VERSION "Version"

NS_ :

BS_:

BU_: CCU ADC FAPA IFC FLR FRR RRR RLR INU Tester CBM VIU SRS IDC PCS AMP IMR FIMR TBOX IBCS IXCU V2XOBU WHUD RLBMS CCURT2 RT2_C3 OTAWL ZCUF ZCUL ZCUR ZCUT IPS DCU NIDU RBM WACUFL IID CCURT1 RT1_C0 RT1_C1 AVAS FLLCM FRLCM RLLCMA RRLCMA RLLCMB RRLCMB LBMS LBMSAD MFS FCP IDU ITS BCB DCDC PCU EOP DCU2 BMS TMC EPS ECS CD PAS SBM WCM ETC TBOX2 DSM FLPDM FRPDM RLPDM RRPDM HVSMR SCMRL SCMRR EBU EPB VDC EVCC ADM PLGM FBLCM RLISD RRISD RCP RFR WCMFR SCMR TFOAR TROAR HVSPRL HVSPRR

BO_ 904 CCU_GwMsg_4: 64 CCU
 SG_ CCU_GwMsg_4_CRC : 7|16@0+ (1,0) [0|65535] ""  ADC
 SG_ CCU_GwMsg_4_Counter : 23|8@0+ (1,0) [0|255] ""  ADC
 SG_ HVAC_RearDefrostSt : 24|1@0+ (1,0) [0|1] ""  ADC
 SG_ HVAC_WindExitMode : 27|3@0+ (1,0) [0|7] ""  ADC
 SG_ HVAC_CorrectedExterTemp : 39|8@0+ (0.5,-40) [-40|87.5] "°C"  ADC
 SG_ HVAC_CorrectedExterTempVD : 28|1@0+ (1,0) [0|1] ""  ADC
 SG_ HVAC_CorrectedCabinTemp : 47|8@0+ (0.5,-40) [-40|87.5] "°C"  ADC
 SG_ HVAC_CorrectedCabinTempVD : 29|1@0+ (1,0) [0|1] ""  ADC
 SG_ WW_FwpFaultSt : 30|1@0+ (1,0) [0|1] ""  ADC
 SG_ WW_RwpFaultSt : 31|1@0+ (1,0) [0|1] ""  ADC
 SG_ WW_FwshFaultSt : 48|1@0+ (1,0) [0|1] ""  ADC
 SG_ WW_RwshFaultSt : 49|1@0+ (1,0) [0|1] ""  ADC
 SG_ WW_FwpAutoModeSt : 50|1@0+ (1,0) [0|1] ""  ADC
 SG_ WW_RainFallLevel : 55|4@0+ (1,0) [0|15] ""  ADC
 SG_ RLS_LightOnReq : 51|1@0+ (1,0) [0|1] ""  ADC
 SG_ RLS_LampOnReqValid : 60|1@0+ (1,0) [0|1] ""  ADC
 SG_ RLS_WiperSpd : 59|4@0+ (1,0) [0|15] ""  ADC
 SG_ RLS_AMBBrightness : 69|14@0+ (6,0) [0|98286] "Lux"  ADC
 SG_ RLS_FWBrightness : 87|14@0+ (6,0) [0|98286] ""  ADC
 SG_ RLS_RainfallLevel : 103|4@0+ (1,0) [0|15] ""  ADC
 SG_ RLS_RSErr : 88|1@0+ (1,0) [0|1] ""  ADC
 SG_ RLS_LSErr : 89|1@0+ (1,0) [0|1] ""  ADC
 SG_ PM_AUTHPstState : 70|1@0+ (1,0) [0|1] ""  ADC
 SG_ CCU_FuncReq_SentryMod : 71|1@0+ (1,0) [0|1] ""  ADC
 SG_ RLS_WindShieldHum : 111|8@0+ (0.5,-0.5) [0|100] "%"  ADC
 SG_ RLS_WindShieldTem : 119|8@0+ (0.5,-40) [-40|86.5] "℃"  ADC
 SG_ RLS_DewPoint : 127|8@0+ (0.5,-40) [-40|86.5] "℃"  ADC
 SG_ CCU_ModeSuppressSts : 62|2@0+ (1,0) [0|2] ""  ADC
 SG_ RLS_HUTErr : 63|1@0+ (1,0) [0|1] ""  ADC
 SG_ SR_SunroofCurrentPst : 135|8@0+ (0.5,0) [0|255] "%"  ADC
 SG_ EL_LeftBSDIndicatorSt : 136|1@0+ (1,0) [0|1] ""  ADC
 SG_ UINM_HazardLightSwSt : 137|1@0+ (1,0) [0|1] ""  ADC
 SG_ EL_MLTurnLightSt : 139|2@0+ (1,0) [0|3] ""  ADC
 SG_ EL_MLTurnLightFaultSt : 140|1@0+ (1,0) [0|1] ""  ADC
 SG_ EL_LeftBSDIndicatorFaultSt : 141|1@0+ (1,0) [0|1] ""  ADC
 SG_ ZCUL_FrtWindshildHeatSt : 143|2@0+ (1,0) [0|3] ""  ADC
 SG_ ACU_PCS_SVM_MODCmd : 96|1@0+ (1,0) [0|1] ""  ADC
 SG_ ACU_HeadLightVirtualSwSt : 99|3@0+ (1,0) [0|7] ""  ADC
 SG_ ACU_FrontFogLightVirtualSwSt : 144|1@0+ (1,0) [0|1] ""  ADC
 SG_ ACU_RearFogLightVirtualSwSt : 145|1@0+ (1,0) [0|1] ""  ADC
 SG_ ACU_Account_Uid : 151|4@0+ (1,0) [0|15] ""  ADC
 SG_ ACU_IHBC_SwitchReq : 147|2@0+ (1,0) [0|3] ""  ADC
 SG_ ACU_NDASwitchReq : 153|2@0+ (1,0) [0|3] ""  ADC
 SG_ ACU_NDALCConSwitchReq : 155|2@0+ (1,0) [0|3] ""  ADC
 SG_ ACU_NDALCStySwitchReq : 157|2@0+ (1,0) [0|3] ""  ADC
 SG_ ACU_ADASWarnTypeSwitch : 159|2@0+ (1,0) [0|3] ""  ADC
 SG_ ACU_iACC_StyleConfirmSwitchReq : 177|2@0+ (1,0) [0|3] ""  ADC
 SG_ ACU_IFC_SpeedLimit : 167|8@0+ (1,0) [0|255] "km/h"  ADC
 SG_ ACU_IFC_ISDRestOfdis : 175|8@0+ (1,0) [0|70] "km"  ADC
 SG_ EL_MLADASLightSt : 181|2@0+ (1,0) [0|3] ""  ADC
 SG_ ACU_IFC_SpeedLimitUnit : 183|2@0+ (1,0) [0|3] ""  ADC
 SG_ ACU_ThemeType : 196|1@0+ (1,0) [0|1] ""  ADC
 SG_ ACU_IFC_SpeedLimtType : 187|4@0+ (1,0) [0|15] ""  ADC
 SG_ ACU_IFC_RoadType : 191|4@0+ (1,0) [0|15] ""  ADC
 SG_ ACU_IFC_ZoneCode : 199|3@0+ (1,0) [0|7] ""  ADC
 SG_ ACU_IFC_NaviSt : 195|2@0+ (1,0) [0|3] ""  ADC
 SG_ ACU_IFC_NaviCorp : 207|3@0+ (1,0) [0|7] ""  ADC
 SG_ ACU_IFC_NaviNewIconDis : 204|5@0+ (0.1,0) [0|2] "km"  ADC
 SG_ ACU_IFC_OfframpSt : 192|1@0+ (1,0) [0|1] ""  ADC
 SG_ ACU_IFC_NaviNewIcon : 211|4@0+ (1,0) [0|15] ""  ADC
 SG_ ACU_IFC_SLCAheadDis : 223|8@0+ (5,0) [0|1250] "m"  ADC
 SG_ ACU_DVR_Switch : 193|1@0+ (1,0) [0|1] ""  ADC
 SG_ ACU_IFC_OfframpDis : 231|8@0+ (10,0) [0|2000] "m"  ADC
 SG_ SSW_FLSeatSlideCurrentPst : 239|8@0+ (0.5,0) [0|100] "%"  ADC
 SG_ SSW_FLSeatHeightCurrentPst : 247|8@0+ (0.5,0) [0|100] "%"  ADC
 SG_ SSW_FLSeatBackrestCurrentPst : 255|8@0+ (0.5,0) [0|100] "%"  ADC
 SG_ DrvrSideMotResp : 263|4@0+ (1,0) [0|15] ""  ADC
 SG_ EL_LeftLowBeamSt : 256|1@0+ (1,0) [0|1] ""  ADC
 SG_ EL_LeftLowBeamFaultSt : 257|1@0+ (1,0) [0|1] ""  ADC
 SG_ EL_RightLowBeamSt : 258|1@0+ (1,0) [0|1] ""  ADC
 SG_ EL_RightLowBeamFaultSt : 259|1@0+ (1,0) [0|1] ""  ADC
 SG_ WW_FWPMotorSt : 271|3@0+ (1,0) [0|7] ""  ADC
 SG_ EL_FLTurnLightSt : 268|2@0+ (1,0) [0|3] ""  ADC
 SG_ EL_FLTurnLightFaultSt : 266|1@0+ (1,0) [0|1] ""  ADC
 SG_ EL_FRTurnLightSt : 265|2@0+ (1,0) [0|3] ""  ADC
 SG_ EL_FRTurnLightFaultSt : 279|1@0+ (1,0) [0|1] ""  ADC
 SG_ EL_SideBrkLightSt : 278|1@0+ (1,0) [0|1] ""  ADC
 SG_ EL_SideBrkLightFaultSt : 277|1@0+ (1,0) [0|1] ""  ADC
 SG_ EL_CHMSLSt : 276|1@0+ (1,0) [0|1] ""  ADC
 SG_ EL_CHMSLFaultSt : 275|1@0+ (1,0) [0|1] ""  ADC
 SG_ EL_RLTurnLightSt : 274|2@0+ (1,0) [0|3] ""  ADC
 SG_ EL_RLTurnLightFaultSt : 272|1@0+ (1,0) [0|1] ""  ADC
 SG_ EL_RRTurnLightSt : 287|2@0+ (1,0) [0|3] ""  ADC
 SG_ EL_RRTurnLightFaultSt : 285|1@0+ (1,0) [0|1] ""  ADC
 SG_ IPS_DCDCModeSt : 298|3@0+ (1,0) [0|7] ""  OTAWL,ADC
 SG_ IPDS_FRRadarPowerSup : 309|2@0+ (1,0) [0|3] ""  ADC
 SG_ IPDS_FLRadarPowerSup : 307|2@0+ (1,0) [0|3] ""  ADC
 SG_ IPDS_FrontRadarPowerSup : 305|2@0+ (1,0) [0|3] ""  ADC
 SG_ IPDS_HDMapPowerSup : 319|2@0+ (1,0) [0|3] ""  ADC
 SG_ IPDS_RearRadarPowerSup : 317|2@0+ (1,0) [0|3] ""  ADC

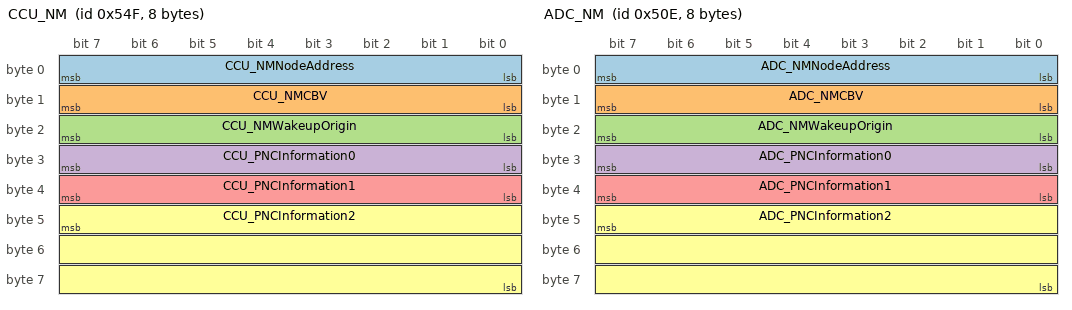
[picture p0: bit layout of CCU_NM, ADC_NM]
BO_ 1359 CCU_NM: 8 CCU
 SG_ CCU_NMNodeAddress : 7|8@0+ (1,0) [0|255] ""  ZCUF,ZCUL,ZCUR,ZCUT,ADM,LBMS,MFS,IDU,ITS,IPS,PCU,DCU,DCU2,NIDU,BMS,EVCC,TMC,RBM,IBCS,ECS,RLBMS,EPB,IXCU,WACUFL,IDC,IID,AMP,ADC,FAPA,VIU,IFC,TBOX,FLPDM,FRPDM,RLPDM,RRPDM,PLGM
 SG_ CCU_NMCBV : 15|8@0+ (1,0) [0|0] ""  ZCUF,ZCUL,ZCUR,ZCUT,ADM,LBMS,MFS,IDU,ITS,IPS,DCDC,PCU,DCU,DCU2,NIDU,BMS,EVCC,TMC,RBM,IBCS,ECS,RLBMS,EPB,IXCU,WACUFL,IDC,IID,AMP,ADC,FAPA,VIU,IFC,TBOX,FLPDM,FRPDM,RLPDM,RRPDM,PLGM
 SG_ CCU_NMWakeupOrigin : 23|8@0+ (1,0) [0|255] ""  ADM,LBMS,IDU,DCU2,TMC,IXCU,WACUFL,IID,AMP,ADC,FAPA,VIU,IFC,FLPDM,FRPDM,RLPDM,RRPDM,PLGM
 SG_ CCU_PNCInformation0 : 31|8@0+ (1,0) [0|255] ""  ZCUF,ZCUL,ZCUR,ZCUT,ADM,LBMS,MFS,IDU,ITS,IPS,DCDC,PCU,DCU,DCU2,NIDU,BMS,EVCC,TMC,RBM,IBCS,ECS,RLBMS,EPB,IXCU,WACUFL,IDC,IID,AMP,ADC,FAPA,VIU,IFC,TBOX,FLPDM,FRPDM,RLPDM,RRPDM,PLGM
 SG_ CCU_PNCInformation1 : 39|8@0+ (1,0) [0|0] ""  ZCUF,ZCUL,ZCUR,ZCUT,ADM,LBMS,MFS,IDU,ITS,IPS,PCU,DCU,DCU2,NIDU,BMS,EVCC,TMC,RBM,IBCS,ECS,RLBMS,EPB,IXCU,WACUFL,IDC,IID,AMP,ADC,FAPA,VIU,IFC,TBOX,FLPDM,FRPDM,RLPDM,RRPDM,PLGM
 SG_ CCU_PNCInformation2 : 47|24@0+ (1,0) [0|0] ""  ZCUF,ZCUL,ZCUR,ZCUT,ADM,LBMS,MFS,IDU,ITS,IPS,PCU,DCU,DCU2,NIDU,BMS,EVCC,TMC,RBM,IBCS,ECS,RLBMS,EPB,IXCU,WACUFL,IDC,IID,AMP,ADC,FAPA,VIU,IFC,TBOX,FLPDM,FRPDM,RLPDM,RRPDM,PLGM

BO_ 1294 ADC_NM: 8 ADC
 SG_ ADC_NMNodeAddress : 7|8@0+ (1,0) [0|255] ""  CCU,RBM,IBCS
 SG_ ADC_NMCBV : 15|8@0+ (1,0) [0|0] ""  CCU,RBM,IBCS
 SG_ ADC_NMWakeupOrigin : 23|8@0+ (1,0) [0|255] ""  CCU,RBM,IBCS
 SG_ ADC_PNCInformation0 : 31|8@0+ (1,0) [0|255] ""  CCU,RBM,IBCS
 SG_ ADC_PNCInformation1 : 39|8@0+ (1,0) [0|0] ""  CCU,RBM,IBCS
 SG_ ADC_PNCInformation2 : 47|24@0+ (1,0) [0|0] ""  CCU,RBM,IBCS

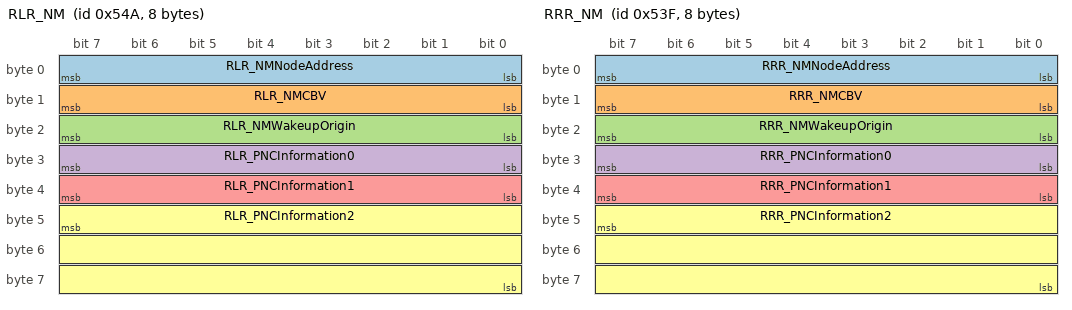
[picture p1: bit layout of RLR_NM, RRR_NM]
BO_ 1354 RLR_NM: 8 RLR
 SG_ RLR_NMNodeAddress : 7|8@0+ (1,0) [0|255] ""  CCU,ADC,FAPA,RRR
 SG_ RLR_NMCBV : 15|8@0+ (1,0) [0|0] ""  CCU,ADC,FAPA,RRR
 SG_ RLR_NMWakeupOrigin : 23|8@0+ (1,0) [0|255] ""  CCU,ADC,FAPA,RRR
 SG_ RLR_PNCInformation0 : 31|8@0+ (1,0) [0|255] ""  CCU,ADC,FAPA,RRR
 SG_ RLR_PNCInformation1 : 39|8@0+ (1,0) [0|0] ""  CCU,ADC,FAPA,RRR
 SG_ RLR_PNCInformation2 : 47|24@0+ (1,0) [0|0] ""  CCU,ADC,FAPA,RRR

BO_ 1343 RRR_NM: 8 RRR
 SG_ RRR_NMNodeAddress : 7|8@0+ (1,0) [0|255] ""  CCU,ADC,FAPA,RLR
 SG_ RRR_NMCBV : 15|8@0+ (1,0) [0|0] ""  CCU,ADC,FAPA,RLR
 SG_ RRR_NMWakeupOrigin : 23|8@0+ (1,0) [0|255] ""  CCU,ADC,FAPA,RLR
 SG_ RRR_PNCInformation0 : 31|8@0+ (1,0) [0|255] ""  CCU,ADC,FAPA,RLR
 SG_ RRR_PNCInformation1 : 39|8@0+ (1,0) [0|0] ""  CCU,ADC,FAPA,RLR
 SG_ RRR_PNCInformation2 : 47|24@0+ (1,0) [0|0] ""  CCU,ADC,FAPA,RLR

BO_ 1188 ADC_BigDataDTC: 64 ADC
 SG_ ADC_DTC : 7|512@0+ (1,0) [0|0] ""  CCU

BO_ 1269 FL_DiagCode: 64 ADC
 SG_ FL_DTCCode : 7|512@0+ (1,0) [0|0] ""  CCU

BO_ 1233 INU_BigDataDTC: 64 INU
 SG_ INU_DTCCode : 7|512@0+ (1,0) [0|1.34078079299426E+154] ""  CCU,ADC,FAPA

BO_ 1238 FR_DiagCode: 64 ADC
 SG_ FR_DTCCode : 7|512@0+ (1,0) [0|0] ""  CCU

BO_ 1934 ADC_Diag_Tx: 64 ADC
 SG_ ADC_Diag_Response : 7|512@0+ (1,0) [0|0] ""  Tester

BO_ 1806 ADC_Phys_Diag_Rx: 64 Tester
 SG_ ADC_Diag_Request : 7|512@0+ (1,0) [0|0] ""  ADC,FAPA,VIU

BO_ 1854 FR_Phys_Diag_Rx: 64 Tester
 SG_ FR_Diag_Request : 7|512@0+ (1,0) [0|0] ""  ADC,FAPA,IFC

BO_ 2015 Fun_Diag_Rx: 64 Tester
 SG_ Fun_Diag_Request : 7|512@0+ (1,0) [0|0] ""  ZCUF,ZCUL,ZCUR,ZCUT,AVAS,FBLCM,FLLCM,FRLCM,RLLCMA,RRLCMA,RLLCMB,RRLCMB,RLISD,RRISD,LBMS,LBMSAD,MFS,FCP,RCP,VDC,ITS,IPS,DCDC,PCU,EOP,DCU,DCU2,NIDU,BMS,EVCC,SRS,EPS,RBM,IBCS,EBU,RLBMS,EPB,IXCU,WACUFL,IDC,IID,CD,AMP,WHUD,IMR,FIMR,ADC,FAPA,VIU,IFC,PAS,PCS,INU,RFR,SBM,WCM,WCMFR,ETC,TBOX,TBOX2,DSM,FLPDM,FRPDM,RLPDM,RRPDM,SCMR,SCMRL,SCMRR,TFOAR,TROAR,HVSPRL,HVSPRR

CM_ SG_ 904 CCU_GwMsg_4_CRC "E2E Profile 5 CRC";
CM_ SG_ 904 CCU_GwMsg_4_Counter "E2E Profile 5 Counter";
CM_ SG_ 904 HVAC_RearDefrostSt "Rear window and mirror heater activation status";
CM_ SG_ 904 HVAC_WindExitMode "The wind exit mode";
CM_ SG_ 904 HVAC_CorrectedExterTemp "Corrected External temperature";
CM_ SG_ 904 HVAC_CorrectedExterTempVD "External temperature valid data";
CM_ SG_ 904 HVAC_CorrectedCabinTemp "Corrected cabin temperature";
CM_ SG_ 904 HVAC_CorrectedCabinTempVD "Signal CorrectedCabinTemp validity";
CM_ SG_ 904 WW_FwpFaultSt "Front Wiper Fault state";
CM_ SG_ 904 WW_RwpFaultSt "Rear Wiper Fault state";
CM_ SG_ 904 WW_FwshFaultSt "Front Washer Fault state";
CM_ SG_ 904 WW_RwshFaultSt "Rear Washer Fault state";
CM_ SG_ 904 WW_FwpAutoModeSt "Front Wiper Auto Mode state";
CM_ SG_ 904 WW_RainFallLevel "Rain Fall Level";
CM_ SG_ 904 RLS_LightOnReq "Switch on/off low beam request";
CM_ SG_ 904 RLS_LampOnReqValid "Lamp On Request signal valid";
CM_ SG_ 904 RLS_WiperSpd "Wiper speed mode";
CM_ SG_ 904 RLS_AMBBrightness "Ambient Light Brightness";
CM_ SG_ 904 RLS_FWBrightness "Forward Light Brightness";
CM_ SG_ 904 RLS_RainfallLevel "Rain level";
CM_ SG_ 904 RLS_RSErr "Error status rain sensor";
CM_ SG_ 904 RLS_LSErr "Error status light sensor";
CM_ SG_ 904 PM_AUTHPstState "位置授权开关状态";
CM_ SG_ 904 CCU_FuncReq_SentryMod "Sentry Mode Wake SOC of MDC";
CM_ SG_ 904 RLS_WindShieldHum "Data windshield humidity";
CM_ SG_ 904 RLS_WindShieldTem "Temperature of the windscreen in ℃";
CM_ SG_ 904 RLS_DewPoint "Dew Temperature of the windscreen in ℃";
CM_ SG_ 904 CCU_ModeSuppressSts "Sentry Mode Suppress Status";
CM_ SG_ 904 RLS_HUTErr "HT sensor status";
CM_ SG_ 904 SR_SunroofCurrentPst "Sunroof current Position";
CM_ SG_ 904 EL_LeftBSDIndicatorSt "Left BSD indicator status";
CM_ SG_ 904 UINM_HazardLightSwSt "Hazard light switch status";
CM_ SG_ 904 EL_MLTurnLightSt "Middle left turn light status";
CM_ SG_ 904 EL_MLTurnLightFaultSt "Middle left turn light fault status";
CM_ SG_ 904 EL_LeftBSDIndicatorFaultSt "Left BSD indicator fault status";
CM_ SG_ 904 ZCUL_FrtWindshildHeatSt "Front windshield heating status";
CM_ SG_ 904 ACU_PCS_SVM_MODCmd "Panorama function setting option MOD function switch";
CM_ SG_ 904 ACU_HeadLightVirtualSwSt "HeadLight virtual switch status";
CM_ SG_ 904 ACU_FrontFogLightVirtualSwSt "Front fog light virtual switch status";
CM_ SG_ 904 ACU_RearFogLightVirtualSwSt "Rear fog light virtual switch status";
CM_ SG_ 904 ACU_Account_Uid "Account_Uid";
CM_ SG_ 904 ACU_IHBC_SwitchReq "IHBC(Intelligent High Beam Control) switch signal";
CM_ SG_ 904 ACU_NDASwitchReq "NDA main switch request";
CM_ SG_ 904 ACU_NDALCConSwitchReq "NDA lane change driver confirm switch request";
CM_ SG_ 904 ACU_NDALCStySwitchReq "NDA lane change style switch request";
CM_ SG_ 904 ACU_ADASWarnTypeSwitch "ADAS warning type switch signal";
CM_ SG_ 904 ACU_iACC_StyleConfirmSwitchReq "iACC Style confirm switch";
CM_ SG_ 904 ACU_IFC_SpeedLimit "Speed limit value from navigation map dataand GPS location.";
CM_ SG_ 904 ACU_IFC_ISDRestOfdis "Interval speed detection rest of distacne.Once navigation jduge vehicle run in aninterval speed detection area of road, thissignal begin to send specific value,otherwise keep sending 0x0.";
CM_ SG_ 904 EL_MLADASLightSt "Middle left ADAS light status";
CM_ SG_ 904 ACU_IFC_SpeedLimitUnit "Speed limit unit";
CM_ SG_ 904 ACU_ThemeType "AVNT theme type";
CM_ SG_ 904 ACU_IFC_SpeedLimtType "speed limit type from navigation map dataand GPS location.";
CM_ SG_ 904 ACU_IFC_RoadType "Road type from navigation map data andGPS location.";
CM_ SG_ 904 ACU_IFC_ZoneCode "Zone code";
CM_ SG_ 904 ACU_IFC_NaviSt "Navigation state";
CM_ SG_ 904 ACU_IFC_NaviCorp "the working navigation map corporation";
CM_ SG_ 904 ACU_IFC_NaviNewIconDis "the remain distances of navigation newIcon";
CM_ SG_ 904 ACU_IFC_OfframpSt "The front is off-ramp or not whennavigation";
CM_ SG_ 904 ACU_IFC_NaviNewIcon "indication the navigation newIcon";
CM_ SG_ 904 ACU_IFC_SLCAheadDis "speed limit camera ahead distacne. Oncenavigation jduge there is a speed limitcamera ahead that the vehicle will pass by,this signal begin to send specific value,otherwise keep sending 0x0.";
CM_ SG_ 904 ACU_DVR_Switch "DVR Function Switch";
CM_ SG_ 904 ACU_IFC_OfframpDis "The distance to front off-ramp";
CM_ SG_ 904 SSW_FLSeatSlideCurrentPst "Front Left Seat Slide Current Position Percentage";
CM_ SG_ 904 SSW_FLSeatHeightCurrentPst "Front Left Seat Height Current Position Percentage";
CM_ SG_ 904 SSW_FLSeatBackrestCurrentPst "Front Left Seat Backrest Current Position Percentage";
CM_ SG_ 904 DrvrSideMotResp "Driver Side Seat Belt Motor Response";
CM_ SG_ 904 EL_LeftLowBeamSt "Left low beam status";
CM_ SG_ 904 EL_LeftLowBeamFaultSt "Left low beam fault status";
CM_ SG_ 904 EL_RightLowBeamSt "Right low beam status";
CM_ SG_ 904 EL_RightLowBeamFaultSt "Right low beam fault status";
CM_ SG_ 904 WW_FWPMotorSt "FrontWiper Motor status";
CM_ SG_ 904 EL_FLTurnLightSt "Front left turn light status";
CM_ SG_ 904 EL_FLTurnLightFaultSt "Front left turn light fault status";
CM_ SG_ 904 EL_FRTurnLightSt "Front right turn light status";
CM_ SG_ 904 EL_FRTurnLightFaultSt "Front right turn light fault status";
CM_ SG_ 904 EL_SideBrkLightSt "Side brake light status";
CM_ SG_ 904 EL_SideBrkLightFaultSt "Side brake light fault status";
CM_ SG_ 904 EL_CHMSLSt "Centre high mounted stop lamp status";
CM_ SG_ 904 EL_CHMSLFaultSt "Centre high mounted stop lamp fault status";
CM_ SG_ 904 EL_RLTurnLightSt "Rear left turn light status";
CM_ SG_ 904 EL_RLTurnLightFaultSt "Rear left turn light fault status";
CM_ SG_ 904 EL_RRTurnLightSt "Rear right turn light status";
CM_ SG_ 904 EL_RRTurnLightFaultSt "Rear right turn light fault status";
CM_ SG_ 904 IPS_DCDCModeSt "mode status of DCDC";
CM_ SG_ 904 IPDS_FRRadarPowerSup "FRR radar power supply";
CM_ SG_ 904 IPDS_FLRadarPowerSup "FLR radar power supply";
CM_ SG_ 904 IPDS_FrontRadarPowerSup "Front radar power supply";
CM_ SG_ 904 IPDS_HDMapPowerSup "HD map power supply";
CM_ SG_ 904 IPDS_RearRadarPowerSup "Rear radar power supply";
CM_ SG_ 1359 CCU_NMNodeAddress "CCU node address";
CM_ SG_ 1359 CCU_NMCBV "CCU Network management  control bit vector";
CM_ SG_ 1359 CCU_NMWakeupOrigin "Origin of the wake up";
CM_ SG_ 1359 CCU_PNCInformation0 "PNC Information";
CM_ SG_ 1359 CCU_PNCInformation1 "PNC Information";
CM_ SG_ 1359 CCU_PNCInformation2 "PNC Information";
CM_ SG_ 1294 ADC_NMNodeAddress "ADC node address";
CM_ SG_ 1294 ADC_NMCBV "ADC Network management  control bit vector";
CM_ SG_ 1294 ADC_NMWakeupOrigin "Origin of the wake up";
CM_ SG_ 1294 ADC_PNCInformation0 "PNC Information";
CM_ SG_ 1294 ADC_PNCInformation1 "PNC Information";
CM_ SG_ 1294 ADC_PNCInformation2 "PNC Information";
CM_ SG_ 1354 RLR_NMNodeAddress "RLR node address";
CM_ SG_ 1354 RLR_NMCBV "RLR Network management control bit vector";
CM_ SG_ 1354 RLR_NMWakeupOrigin "Origin of the wake up";
CM_ SG_ 1354 RLR_PNCInformation0 "PNC Information";
CM_ SG_ 1354 RLR_PNCInformation1 "PNC Information";
CM_ SG_ 1354 RLR_PNCInformation2 "PNC Information";
CM_ SG_ 1343 RRR_NMNodeAddress "RRR node address";
CM_ SG_ 1343 RRR_NMCBV "RRR Network management control bit vector";
CM_ SG_ 1343 RRR_NMWakeupOrigin "Origin of the wake up";
CM_ SG_ 1343 RRR_PNCInformation0 "PNC Information";
CM_ SG_ 1343 RRR_PNCInformation1 "PNC Information";
CM_ SG_ 1343 RRR_PNCInformation2 "PNC Information";
CM_ SG_ 1188 ADC_DTC "信号用于上报ADC的故障信息，信号长度64个字节，存储16个故障码?每个故障码由4个字节构成：DTCHighByte(Hex)DTCMiddleByte(Hex)DTCLowByte(Hex)StatusOfDTC";
CM_ SG_ 1269 FL_DTCCode "FL DTC and status Sent To CCU";
CM_ SG_ 1233 INU_DTCCode "INU DTC code and status";
CM_ SG_ 1238 FR_DTCCode "DTC Sent To CCU";
CM_ SG_ 1934 ADC_Diag_Response "ADC diagnostic response";
CM_ SG_ 1806 ADC_Diag_Request "Diagnostic physical request";
CM_ SG_ 1854 FR_Diag_Request "Diagnostic physical request";
CM_ SG_ 2015 Fun_Diag_Request "Diagnostic function request";

BA_DEF_ BO_  "GenMsgCycleTime" INT 0 0;
BA_DEF_ BO_  "GenMsgCycleTimeFast" INT 0 0;
BA_DEF_ BO_  "GenMsgSendType" ENUM  "Periodic","Event","IfActive","POE","PA","FixedPeriodic","Event","EnabledPeriodic","NotUsed","NotUsed","EventPeriodic","NotUsed","NotUsed","NoMsgSendType";
BA_DEF_ BO_  "VFrameFormat" ENUM  "StandardCAN","ExtendedCAN","reserved","reserved","reserved","reserved","reserved","reserved","reserved","reserved","reserved","reserved","reserved","reserved","StandardCAN_FD","ExtendedCAN_FD";
BA_DEF_ BO_  "CANFD_BRS" ENUM  "0","1";
BA_DEF_ SG_  "EventCommandSignal" ENUM  "No","Yes";
BA_DEF_ SG_  "GatewayedSignals" ENUM  "No","Yes";
BA_DEF_ SG_  "GenSigInactiveValue" HEX 0 0;
BA_DEF_ SG_  "GenSigInvalidValue" HEX 0 0;
BA_DEF_ SG_  "GenSigSendType" ENUM  "Trigger","Passive","Cyclic","OnWrite","OnWriteWithRepetition","OnChange","OnChangeWithRepetition","IfActive","IfActiveWithRepetition","NoSigSendType";
BA_DEF_ SG_  "GenSigStartValue" HEX 0 0;
BA_DEF_ SG_  "GenSigTimeoutValue" HEX 0 0;
BA_DEF_ SG_  "Remark" STRING ;
BA_ "GenMsgCycleTime" BO_ 904 100;
BA_ "GenMsgCycleTimeFast" BO_ 904 0;
BA_ "GenMsgSendType" BO_ 904 0;
BA_ "VFrameFormat" BO_ 904 14;
BA_ "CANFD_BRS" BO_ 904 1;
BA_ "GenMsgCycleTime" BO_ 904 100;
BA_ "GenMsgCycleTimeFast" BO_ 904 0;
BA_ "GenMsgSendType" BO_ 904 0;
BA_ "VFrameFormat" BO_ 904 14;
BA_ "CANFD_BRS" BO_ 904 1;
BA_ "GenMsgCycleTime" BO_ 904 100;
BA_ "GenMsgCycleTimeFast" BO_ 904 0;
BA_ "GenMsgSendType" BO_ 904 0;
BA_ "VFrameFormat" BO_ 904 14;
BA_ "CANFD_BRS" BO_ 904 1;
BA_ "GenMsgCycleTime" BO_ 904 100;
BA_ "GenMsgCycleTimeFast" BO_ 904 0;
BA_ "GenMsgSendType" BO_ 904 0;
BA_ "VFrameFormat" BO_ 904 14;
BA_ "CANFD_BRS" BO_ 904 1;
BA_ "GenMsgCycleTime" BO_ 904 100;
BA_ "GenMsgCycleTimeFast" BO_ 904 0;
BA_ "GenMsgSendType" BO_ 904 0;
BA_ "VFrameFormat" BO_ 904 14;
BA_ "CANFD_BRS" BO_ 904 1;
BA_ "GenMsgCycleTime" BO_ 904 100;
BA_ "GenMsgCycleTimeFast" BO_ 904 0;
BA_ "GenMsgSendType" BO_ 904 0;
BA_ "VFrameFormat" BO_ 904 14;
BA_ "CANFD_BRS" BO_ 904 1;
BA_ "GenMsgCycleTime" BO_ 904 100;
BA_ "GenMsgCycleTimeFast" BO_ 904 0;
BA_ "GenMsgSendType" BO_ 904 0;
BA_ "VFrameFormat" BO_ 904 14;
BA_ "CANFD_BRS" BO_ 904 1;
BA_ "GenMsgCycleTime" BO_ 904 100;
BA_ "GenMsgCycleTimeFast" BO_ 904 0;
BA_ "GenMsgSendType" BO_ 904 0;
BA_ "VFrameFormat" BO_ 904 14;
BA_ "CANFD_BRS" BO_ 904 1;
BA_ "GenMsgCycleTime" BO_ 904 100;
BA_ "GenMsgCycleTimeFast" BO_ 904 0;
BA_ "GenMsgSendType" BO_ 904 0;
BA_ "VFrameFormat" BO_ 904 14;
BA_ "CANFD_BRS" BO_ 904 1;
BA_ "GenMsgCycleTime" BO_ 904 100;
BA_ "GenMsgCycleTimeFast" BO_ 904 0;
BA_ "GenMsgSendType" BO_ 904 0;
BA_ "VFrameFormat" BO_ 904 14;
BA_ "CANFD_BRS" BO_ 904 1;
BA_ "GenMsgCycleTime" BO_ 904 100;
BA_ "GenMsgCycleTimeFast" BO_ 904 0;
BA_ "GenMsgSendType" BO_ 904 0;
BA_ "VFrameFormat" BO_ 904 14;
BA_ "CANFD_BRS" BO_ 904 1;
BA_ "GenMsgCycleTime" BO_ 904 100;
BA_ "GenMsgCycleTimeFast" BO_ 904 0;
BA_ "GenMsgSendType" BO_ 904 0;
BA_ "VFrameFormat" BO_ 904 14;
BA_ "CANFD_BRS" BO_ 904 1;
BA_ "GenMsgCycleTime" BO_ 904 100;
BA_ "GenMsgCycleTimeFast" BO_ 904 0;
BA_ "GenMsgSendType" BO_ 904 0;
BA_ "VFrameFormat" BO_ 904 14;
BA_ "CANFD_BRS" BO_ 904 1;
BA_ "GenMsgCycleTime" BO_ 904 100;
BA_ "GenMsgCycleTimeFast" BO_ 904 0;
BA_ "GenMsgSendType" BO_ 904 0;
BA_ "VFrameFormat" BO_ 904 14;
BA_ "CANFD_BRS" BO_ 904 1;
BA_ "GenMsgCycleTime" BO_ 904 100;
BA_ "GenMsgCycleTimeFast" BO_ 904 0;
BA_ "GenMsgSendType" BO_ 904 0;
BA_ "VFrameFormat" BO_ 904 14;
BA_ "CANFD_BRS" BO_ 904 1;
BA_ "GenMsgCycleTime" BO_ 904 100;
BA_ "GenMsgCycleTimeFast" BO_ 904 0;
BA_ "GenMsgSendType" BO_ 904 0;
BA_ "VFrameFormat" BO_ 904 14;
BA_ "CANFD_BRS" BO_ 904 1;
BA_ "GenMsgCycleTime" BO_ 904 100;
BA_ "GenMsgCycleTimeFast" BO_ 904 0;
BA_ "GenMsgSendType" BO_ 904 0;
BA_ "VFrameFormat" BO_ 904 14;
BA_ "CANFD_BRS" BO_ 904 1;
BA_ "GenMsgCycleTime" BO_ 904 100;
BA_ "GenMsgCycleTimeFast" BO_ 904 0;
BA_ "GenMsgSendType" BO_ 904 0;
BA_ "VFrameFormat" BO_ 904 14;
BA_ "CANFD_BRS" BO_ 904 1;
BA_ "GenMsgCycleTime" BO_ 904 100;
BA_ "GenMsgCycleTimeFast" BO_ 904 0;
BA_ "GenMsgSendType" BO_ 904 0;
BA_ "VFrameFormat" BO_ 904 14;
BA_ "CANFD_BRS" BO_ 904 1;
BA_ "GenMsgCycleTime" BO_ 904 100;
BA_ "GenMsgCycleTimeFast" BO_ 904 0;
BA_ "GenMsgSendType" BO_ 904 0;
BA_ "VFrameFormat" BO_ 904 14;
BA_ "CANFD_BRS" BO_ 904 1;
BA_ "GenMsgCycleTime" BO_ 904 100;
BA_ "GenMsgCycleTimeFast" BO_ 904 0;
BA_ "GenMsgSendType" BO_ 904 0;
BA_ "VFrameFormat" BO_ 904 14;
BA_ "CANFD_BRS" BO_ 904 1;
BA_ "GenMsgCycleTime" BO_ 904 100;
BA_ "GenMsgCycleTimeFast" BO_ 904 0;
BA_ "GenMsgSendType" BO_ 904 0;
BA_ "VFrameFormat" BO_ 904 14;
BA_ "CANFD_BRS" BO_ 904 1;
BA_ "GenMsgCycleTime" BO_ 904 100;
BA_ "GenMsgCycleTimeFast" BO_ 904 0;
BA_ "GenMsgSendType" BO_ 904 0;
BA_ "VFrameFormat" BO_ 904 14;
BA_ "CANFD_BRS" BO_ 904 1;
BA_ "GenMsgCycleTime" BO_ 904 100;
BA_ "GenMsgCycleTimeFast" BO_ 904 0;
BA_ "GenMsgSendType" BO_ 904 0;
BA_ "VFrameFormat" BO_ 904 14;
BA_ "CANFD_BRS" BO_ 904 1;
BA_ "GenMsgCycleTime" BO_ 904 100;
BA_ "GenMsgCycleTimeFast" BO_ 904 0;
BA_ "GenMsgSendType" BO_ 904 0;
BA_ "VFrameFormat" BO_ 904 14;
BA_ "CANFD_BRS" BO_ 904 1;
BA_ "GenMsgCycleTime" BO_ 904 100;
BA_ "GenMsgCycleTimeFast" BO_ 904 0;
BA_ "GenMsgSendType" BO_ 904 0;
BA_ "VFrameFormat" BO_ 904 14;
BA_ "CANFD_BRS" BO_ 904 1;
BA_ "GenMsgCycleTime" BO_ 904 100;
BA_ "GenMsgCycleTimeFast" BO_ 904 0;
BA_ "GenMsgSendType" BO_ 904 0;
BA_ "VFrameFormat" BO_ 904 14;
BA_ "CANFD_BRS" BO_ 904 1;
BA_ "GenMsgCycleTime" BO_ 904 100;
BA_ "GenMsgCycleTimeFast" BO_ 904 0;
BA_ "GenMsgSendType" BO_ 904 0;
BA_ "VFrameFormat" BO_ 904 14;
BA_ "CANFD_BRS" BO_ 904 1;
BA_ "GenMsgCycleTime" BO_ 904 100;
BA_ "GenMsgCycleTimeFast" BO_ 904 0;
BA_ "GenMsgSendType" BO_ 904 0;
BA_ "VFrameFormat" BO_ 904 14;
BA_ "CANFD_BRS" BO_ 904 1;
BA_ "GenMsgCycleTime" BO_ 904 100;
BA_ "GenMsgCycleTimeFast" BO_ 904 0;
BA_ "GenMsgSendType" BO_ 904 0;
BA_ "VFrameFormat" BO_ 904 14;
BA_ "CANFD_BRS" BO_ 904 1;
BA_ "GenMsgCycleTime" BO_ 904 100;
BA_ "GenMsgCycleTimeFast" BO_ 904 0;
BA_ "GenMsgSendType" BO_ 904 0;
BA_ "VFrameFormat" BO_ 904 14;
BA_ "CANFD_BRS" BO_ 904 1;
BA_ "GenMsgCycleTime" BO_ 904 100;
BA_ "GenMsgCycleTimeFast" BO_ 904 0;
BA_ "GenMsgSendType" BO_ 904 0;
BA_ "VFrameFormat" BO_ 904 14;
BA_ "CANFD_BRS" BO_ 904 1;
BA_ "GenMsgCycleTime" BO_ 904 100;
BA_ "GenMsgCycleTimeFast" BO_ 904 0;
BA_ "GenMsgSendType" BO_ 904 0;
BA_ "VFrameFormat" BO_ 904 14;
BA_ "CANFD_BRS" BO_ 904 1;
BA_ "GenMsgCycleTime" BO_ 904 100;
BA_ "GenMsgCycleTimeFast" BO_ 904 0;
BA_ "GenMsgSendType" BO_ 904 0;
BA_ "VFrameFormat" BO_ 904 14;
BA_ "CANFD_BRS" BO_ 904 1;
BA_ "GenMsgCycleTime" BO_ 904 100;
BA_ "GenMsgCycleTimeFast" BO_ 904 0;
BA_ "GenMsgSendType" BO_ 904 0;
BA_ "VFrameFormat" BO_ 904 14;
BA_ "CANFD_BRS" BO_ 904 1;
BA_ "GenMsgCycleTime" BO_ 904 100;
BA_ "GenMsgCycleTimeFast" BO_ 904 0;
BA_ "GenMsgSendType" BO_ 904 0;
BA_ "VFrameFormat" BO_ 904 14;
BA_ "CANFD_BRS" BO_ 904 1;
BA_ "GenMsgCycleTime" BO_ 904 100;
BA_ "GenMsgCycleTimeFast" BO_ 904 0;
BA_ "GenMsgSendType" BO_ 904 0;
BA_ "VFrameFormat" BO_ 904 14;
BA_ "CANFD_BRS" BO_ 904 1;
BA_ "GenMsgCycleTime" BO_ 904 100;
BA_ "GenMsgCycleTimeFast" BO_ 904 0;
BA_ "GenMsgSendType" BO_ 904 0;
BA_ "VFrameFormat" BO_ 904 14;
BA_ "CANFD_BRS" BO_ 904 1;
BA_ "GenMsgCycleTime" BO_ 904 100;
BA_ "GenMsgCycleTimeFast" BO_ 904 0;
BA_ "GenMsgSendType" BO_ 904 0;
BA_ "VFrameFormat" BO_ 904 14;
BA_ "CANFD_BRS" BO_ 904 1;
BA_ "GenMsgCycleTime" BO_ 904 100;
BA_ "GenMsgCycleTimeFast" BO_ 904 0;
BA_ "GenMsgSendType" BO_ 904 0;
BA_ "VFrameFormat" BO_ 904 14;
BA_ "CANFD_BRS" BO_ 904 1;
BA_ "GenMsgCycleTime" BO_ 904 100;
BA_ "GenMsgCycleTimeFast" BO_ 904 0;
BA_ "GenMsgSendType" BO_ 904 0;
BA_ "VFrameFormat" BO_ 904 14;
BA_ "CANFD_BRS" BO_ 904 1;
BA_ "GenMsgCycleTime" BO_ 904 100;
BA_ "GenMsgCycleTimeFast" BO_ 904 0;
BA_ "GenMsgSendType" BO_ 904 0;
BA_ "VFrameFormat" BO_ 904 14;
BA_ "CANFD_BRS" BO_ 904 1;
BA_ "GenMsgCycleTime" BO_ 904 100;
BA_ "GenMsgCycleTimeFast" BO_ 904 0;
BA_ "GenMsgSendType" BO_ 904 0;
BA_ "VFrameFormat" BO_ 904 14;
BA_ "CANFD_BRS" BO_ 904 1;
BA_ "GenMsgCycleTime" BO_ 904 100;
BA_ "GenMsgCycleTimeFast" BO_ 904 0;
BA_ "GenMsgSendType" BO_ 904 0;
BA_ "VFrameFormat" BO_ 904 14;
BA_ "CANFD_BRS" BO_ 904 1;
BA_ "GenMsgCycleTime" BO_ 904 100;
BA_ "GenMsgCycleTimeFast" BO_ 904 0;
BA_ "GenMsgSendType" BO_ 904 0;
BA_ "VFrameFormat" BO_ 904 14;
BA_ "CANFD_BRS" BO_ 904 1;
BA_ "GenMsgCycleTime" BO_ 904 100;
BA_ "GenMsgCycleTimeFast" BO_ 904 0;
BA_ "GenMsgSendType" BO_ 904 0;
BA_ "VFrameFormat" BO_ 904 14;
BA_ "CANFD_BRS" BO_ 904 1;
BA_ "GenMsgCycleTime" BO_ 904 100;
BA_ "GenMsgCycleTimeFast" BO_ 904 0;
BA_ "GenMsgSendType" BO_ 904 0;
BA_ "VFrameFormat" BO_ 904 14;
BA_ "CANFD_BRS" BO_ 904 1;
BA_ "GenMsgCycleTime" BO_ 904 100;
BA_ "GenMsgCycleTimeFast" BO_ 904 0;
BA_ "GenMsgSendType" BO_ 904 0;
BA_ "VFrameFormat" BO_ 904 14;
BA_ "CANFD_BRS" BO_ 904 1;
BA_ "GenMsgCycleTime" BO_ 904 100;
BA_ "GenMsgCycleTimeFast" BO_ 904 0;
BA_ "GenMsgSendType" BO_ 904 0;
BA_ "VFrameFormat" BO_ 904 14;
BA_ "CANFD_BRS" BO_ 904 1;
BA_ "GenMsgCycleTime" BO_ 904 100;
BA_ "GenMsgCycleTimeFast" BO_ 904 0;
BA_ "GenMsgSendType" BO_ 904 0;
BA_ "VFrameFormat" BO_ 904 14;
BA_ "CANFD_BRS" BO_ 904 1;
BA_ "GenMsgCycleTime" BO_ 904 100;
BA_ "GenMsgCycleTimeFast" BO_ 904 0;
BA_ "GenMsgSendType" BO_ 904 0;
BA_ "VFrameFormat" BO_ 904 14;
BA_ "CANFD_BRS" BO_ 904 1;
BA_ "GenMsgCycleTime" BO_ 904 100;
BA_ "GenMsgCycleTimeFast" BO_ 904 0;
BA_ "GenMsgSendType" BO_ 904 0;
BA_ "VFrameFormat" BO_ 904 14;
BA_ "CANFD_BRS" BO_ 904 1;
BA_ "GenMsgCycleTime" BO_ 904 100;
BA_ "GenMsgCycleTimeFast" BO_ 904 0;
BA_ "GenMsgSendType" BO_ 904 0;
BA_ "VFrameFormat" BO_ 904 14;
BA_ "CANFD_BRS" BO_ 904 1;
BA_ "GenMsgCycleTime" BO_ 904 100;
BA_ "GenMsgCycleTimeFast" BO_ 904 0;
BA_ "GenMsgSendType" BO_ 904 0;
BA_ "VFrameFormat" BO_ 904 14;
BA_ "CANFD_BRS" BO_ 904 1;
BA_ "GenMsgCycleTime" BO_ 904 100;
BA_ "GenMsgCycleTimeFast" BO_ 904 0;
BA_ "GenMsgSendType" BO_ 904 0;
BA_ "VFrameFormat" BO_ 904 14;
BA_ "CANFD_BRS" BO_ 904 1;
BA_ "GenMsgCycleTime" BO_ 904 100;
BA_ "GenMsgCycleTimeFast" BO_ 904 0;
BA_ "GenMsgSendType" BO_ 904 0;
BA_ "VFrameFormat" BO_ 904 14;
BA_ "CANFD_BRS" BO_ 904 1;
BA_ "GenMsgCycleTime" BO_ 904 100;
BA_ "GenMsgCycleTimeFast" BO_ 904 0;
BA_ "GenMsgSendType" BO_ 904 0;
BA_ "VFrameFormat" BO_ 904 14;
BA_ "CANFD_BRS" BO_ 904 1;
BA_ "GenMsgCycleTime" BO_ 904 100;
BA_ "GenMsgCycleTimeFast" BO_ 904 0;
BA_ "GenMsgSendType" BO_ 904 0;
BA_ "VFrameFormat" BO_ 904 14;
BA_ "CANFD_BRS" BO_ 904 1;
BA_ "GenMsgCycleTime" BO_ 904 100;
BA_ "GenMsgCycleTimeFast" BO_ 904 0;
BA_ "GenMsgSendType" BO_ 904 0;
BA_ "VFrameFormat" BO_ 904 14;
BA_ "CANFD_BRS" BO_ 904 1;
BA_ "GenMsgCycleTime" BO_ 904 100;
BA_ "GenMsgCycleTimeFast" BO_ 904 0;
BA_ "GenMsgSendType" BO_ 904 0;
BA_ "VFrameFormat" BO_ 904 14;
BA_ "CANFD_BRS" BO_ 904 1;
BA_ "GenMsgCycleTime" BO_ 904 100;
BA_ "GenMsgCycleTimeFast" BO_ 904 0;
BA_ "GenMsgSendType" BO_ 904 0;
BA_ "VFrameFormat" BO_ 904 14;
BA_ "CANFD_BRS" BO_ 904 1;
BA_ "GenMsgCycleTime" BO_ 904 100;
BA_ "GenMsgCycleTimeFast" BO_ 904 0;
BA_ "GenMsgSendType" BO_ 904 0;
BA_ "VFrameFormat" BO_ 904 14;
BA_ "CANFD_BRS" BO_ 904 1;
BA_ "GenMsgCycleTime" BO_ 904 100;
BA_ "GenMsgCycleTimeFast" BO_ 904 0;
BA_ "GenMsgSendType" BO_ 904 0;
BA_ "VFrameFormat" BO_ 904 14;
BA_ "CANFD_BRS" BO_ 904 1;
BA_ "GenMsgCycleTime" BO_ 904 100;
BA_ "GenMsgCycleTimeFast" BO_ 904 0;
BA_ "GenMsgSendType" BO_ 904 0;
BA_ "VFrameFormat" BO_ 904 14;
BA_ "CANFD_BRS" BO_ 904 1;
BA_ "GenMsgCycleTime" BO_ 904 100;
BA_ "GenMsgCycleTimeFast" BO_ 904 0;
BA_ "GenMsgSendType" BO_ 904 0;
BA_ "VFrameFormat" BO_ 904 14;
BA_ "CANFD_BRS" BO_ 904 1;
BA_ "GenMsgCycleTime" BO_ 904 100;
BA_ "GenMsgCycleTimeFast" BO_ 904 0;
BA_ "GenMsgSendType" BO_ 904 0;
BA_ "VFrameFormat" BO_ 904 14;
BA_ "CANFD_BRS" BO_ 904 1;
BA_ "GenMsgCycleTime" BO_ 904 100;
BA_ "GenMsgCycleTimeFast" BO_ 904 0;
BA_ "GenMsgSendType" BO_ 904 0;
BA_ "VFrameFormat" BO_ 904 14;
BA_ "CANFD_BRS" BO_ 904 1;
BA_ "GenMsgCycleTime" BO_ 904 100;
BA_ "GenMsgCycleTimeFast" BO_ 904 0;
BA_ "GenMsgSendType" BO_ 904 0;
BA_ "VFrameFormat" BO_ 904 14;
BA_ "CANFD_BRS" BO_ 904 1;
BA_ "GenMsgCycleTime" BO_ 904 100;
BA_ "GenMsgCycleTimeFast" BO_ 904 0;
BA_ "GenMsgSendType" BO_ 904 0;
BA_ "VFrameFormat" BO_ 904 14;
BA_ "CANFD_BRS" BO_ 904 1;
BA_ "GenMsgCycleTime" BO_ 904 100;
BA_ "GenMsgCycleTimeFast" BO_ 904 0;
BA_ "GenMsgSendType" BO_ 904 0;
BA_ "VFrameFormat" BO_ 904 14;
BA_ "CANFD_BRS" BO_ 904 1;
BA_ "GenMsgCycleTime" BO_ 904 100;
BA_ "GenMsgCycleTimeFast" BO_ 904 0;
BA_ "GenMsgSendType" BO_ 904 0;
BA_ "VFrameFormat" BO_ 904 14;
BA_ "CANFD_BRS" BO_ 904 1;
BA_ "GenMsgCycleTime" BO_ 904 100;
BA_ "GenMsgCycleTimeFast" BO_ 904 0;
BA_ "GenMsgSendType" BO_ 904 0;
BA_ "VFrameFormat" BO_ 904 14;
BA_ "CANFD_BRS" BO_ 904 1;
BA_ "GenMsgCycleTime" BO_ 904 100;
BA_ "GenMsgCycleTimeFast" BO_ 904 0;
BA_ "GenMsgSendType" BO_ 904 0;
BA_ "VFrameFormat" BO_ 904 14;
BA_ "CANFD_BRS" BO_ 904 1;
BA_ "GenMsgCycleTime" BO_ 904 100;
BA_ "GenMsgCycleTimeFast" BO_ 904 0;
BA_ "GenMsgSendType" BO_ 904 0;
BA_ "VFrameFormat" BO_ 904 14;
BA_ "CANFD_BRS" BO_ 904 1;
BA_ "GenMsgCycleTime" BO_ 904 100;
BA_ "GenMsgCycleTimeFast" BO_ 904 0;
BA_ "GenMsgSendType" BO_ 904 0;
BA_ "VFrameFormat" BO_ 904 14;
BA_ "CANFD_BRS" BO_ 904 1;
BA_ "GenMsgCycleTime" BO_ 904 100;
BA_ "GenMsgCycleTimeFast" BO_ 904 0;
BA_ "GenMsgSendType" BO_ 904 0;
BA_ "VFrameFormat" BO_ 904 14;
BA_ "CANFD_BRS" BO_ 904 1;
BA_ "GenMsgCycleTime" BO_ 904 100;
BA_ "GenMsgCycleTimeFast" BO_ 904 0;
BA_ "GenMsgSendType" BO_ 904 0;
BA_ "VFrameFormat" BO_ 904 14;
BA_ "CANFD_BRS" BO_ 904 1;
BA_ "GenMsgCycleTime" BO_ 904 100;
BA_ "GenMsgCycleTimeFast" BO_ 904 0;
BA_ "GenMsgSendType" BO_ 904 0;
BA_ "VFrameFormat" BO_ 904 14;
BA_ "CANFD_BRS" BO_ 904 1;
BA_ "GenMsgCycleTime" BO_ 904 100;
BA_ "GenMsgCycleTimeFast" BO_ 904 0;
BA_ "GenMsgSendType" BO_ 904 0;
BA_ "VFrameFormat" BO_ 904 14;
BA_ "CANFD_BRS" BO_ 904 1;
BA_ "GenMsgCycleTime" BO_ 904 100;
BA_ "GenMsgCycleTimeFast" BO_ 904 0;
BA_ "GenMsgSendType" BO_ 904 0;
BA_ "VFrameFormat" BO_ 904 14;
BA_ "CANFD_BRS" BO_ 904 1;
BA_ "GenMsgCycleTime" BO_ 904 100;
BA_ "GenMsgCycleTimeFast" BO_ 904 0;
BA_ "GenMsgSendType" BO_ 904 0;
BA_ "VFrameFormat" BO_ 904 14;
BA_ "CANFD_BRS" BO_ 904 1;
BA_ "GenMsgCycleTime" BO_ 904 100;
BA_ "GenMsgCycleTimeFast" BO_ 904 0;
BA_ "GenMsgSendType" BO_ 904 0;
BA_ "VFrameFormat" BO_ 904 14;
BA_ "CANFD_BRS" BO_ 904 1;
BA_ "GenMsgCycleTime" BO_ 904 100;
BA_ "GenMsgCycleTimeFast" BO_ 904 0;
BA_ "GenMsgSendType" BO_ 904 0;
BA_ "VFrameFormat" BO_ 904 14;
BA_ "CANFD_BRS" BO_ 904 1;
BA_ "GenMsgCycleTime" BO_ 904 100;
BA_ "GenMsgCycleTimeFast" BO_ 904 0;
BA_ "GenMsgSendType" BO_ 904 0;
BA_ "VFrameFormat" BO_ 904 14;
BA_ "CANFD_BRS" BO_ 904 1;
BA_ "GenMsgCycleTime" BO_ 904 100;
BA_ "GenMsgCycleTimeFast" BO_ 904 0;
BA_ "GenMsgSendType" BO_ 904 0;
BA_ "VFrameFormat" BO_ 904 14;
BA_ "CANFD_BRS" BO_ 904 1;
BA_ "GenMsgCycleTime" BO_ 904 100;
BA_ "GenMsgCycleTimeFast" BO_ 904 0;
BA_ "GenMsgSendType" BO_ 904 0;
BA_ "VFrameFormat" BO_ 904 14;
BA_ "CANFD_BRS" BO_ 904 1;
BA_ "GenMsgCycleTime" BO_ 904 100;
BA_ "GenMsgCycleTimeFast" BO_ 904 0;
BA_ "GenMsgSendType" BO_ 904 0;
BA_ "VFrameFormat" BO_ 904 14;
BA_ "CANFD_BRS" BO_ 904 1;
BA_ "GenMsgCycleTime" BO_ 904 100;
BA_ "GenMsgCycleTimeFast" BO_ 904 0;
BA_ "GenMsgSendType" BO_ 904 0;
BA_ "VFrameFormat" BO_ 904 14;
BA_ "CANFD_BRS" BO_ 904 1;
BA_ "GenMsgCycleTime" BO_ 904 100;
BA_ "GenMsgCycleTimeFast" BO_ 904 0;
BA_ "GenMsgSendType" BO_ 904 0;
BA_ "VFrameFormat" BO_ 904 14;
BA_ "CANFD_BRS" BO_ 904 1;
BA_ "GenMsgCycleTime" BO_ 904 100;
BA_ "GenMsgCycleTimeFast" BO_ 904 0;
BA_ "GenMsgSendType" BO_ 904 0;
BA_ "VFrameFormat" BO_ 904 14;
BA_ "CANFD_BRS" BO_ 904 1;
BA_ "GenMsgCycleTime" BO_ 1359 200;
BA_ "GenMsgCycleTimeFast" BO_ 1359 0;
BA_ "GenMsgSendType" BO_ 1359 0;
BA_ "VFrameFormat" BO_ 1359 0;
BA_ "CANFD_BRS" BO_ 1359 1;
BA_ "GenMsgCycleTime" BO_ 1359 200;
BA_ "GenMsgCycleTimeFast" BO_ 1359 0;
BA_ "GenMsgSendType" BO_ 1359 0;
BA_ "VFrameFormat" BO_ 1359 0;
BA_ "CANFD_BRS" BO_ 1359 1;
BA_ "GenMsgCycleTime" BO_ 1359 200;
BA_ "GenMsgCycleTimeFast" BO_ 1359 0;
BA_ "GenMsgSendType" BO_ 1359 0;
BA_ "VFrameFormat" BO_ 1359 0;
BA_ "CANFD_BRS" BO_ 1359 1;
BA_ "GenMsgCycleTime" BO_ 1359 200;
BA_ "GenMsgCycleTimeFast" BO_ 1359 0;
BA_ "GenMsgSendType" BO_ 1359 0;
BA_ "VFrameFormat" BO_ 1359 0;
BA_ "CANFD_BRS" BO_ 1359 1;
BA_ "GenMsgCycleTime" BO_ 1359 200;
BA_ "GenMsgCycleTimeFast" BO_ 1359 0;
BA_ "GenMsgSendType" BO_ 1359 0;
BA_ "VFrameFormat" BO_ 1359 0;
BA_ "CANFD_BRS" BO_ 1359 1;
BA_ "GenMsgCycleTime" BO_ 1359 200;
BA_ "GenMsgCycleTimeFast" BO_ 1359 0;
BA_ "GenMsgSendType" BO_ 1359 0;
BA_ "VFrameFormat" BO_ 1359 0;
BA_ "CANFD_BRS" BO_ 1359 1;
BA_ "GenMsgCycleTime" BO_ 1294 200;
BA_ "GenMsgCycleTimeFast" BO_ 1294 0;
BA_ "GenMsgSendType" BO_ 1294 0;
BA_ "VFrameFormat" BO_ 1294 0;
BA_ "CANFD_BRS" BO_ 1294 1;
BA_ "GenMsgCycleTime" BO_ 1294 200;
BA_ "GenMsgCycleTimeFast" BO_ 1294 0;
BA_ "GenMsgSendType" BO_ 1294 0;
BA_ "VFrameFormat" BO_ 1294 0;
BA_ "CANFD_BRS" BO_ 1294 1;
BA_ "GenMsgCycleTime" BO_ 1294 200;
BA_ "GenMsgCycleTimeFast" BO_ 1294 0;
BA_ "GenMsgSendType" BO_ 1294 0;
BA_ "VFrameFormat" BO_ 1294 0;
BA_ "CANFD_BRS" BO_ 1294 1;
BA_ "GenMsgCycleTime" BO_ 1294 200;
BA_ "GenMsgCycleTimeFast" BO_ 1294 0;
BA_ "GenMsgSendType" BO_ 1294 0;
BA_ "VFrameFormat" BO_ 1294 0;
BA_ "CANFD_BRS" BO_ 1294 1;
BA_ "GenMsgCycleTime" BO_ 1294 200;
BA_ "GenMsgCycleTimeFast" BO_ 1294 0;
BA_ "GenMsgSendType" BO_ 1294 0;
BA_ "VFrameFormat" BO_ 1294 0;
BA_ "CANFD_BRS" BO_ 1294 1;
BA_ "GenMsgCycleTime" BO_ 1294 200;
BA_ "GenMsgCycleTimeFast" BO_ 1294 0;
BA_ "GenMsgSendType" BO_ 1294 0;
BA_ "VFrameFormat" BO_ 1294 0;
BA_ "CANFD_BRS" BO_ 1294 1;
BA_ "GenMsgCycleTime" BO_ 1354 200;
BA_ "GenMsgCycleTimeFast" BO_ 1354 0;
BA_ "GenMsgSendType" BO_ 1354 0;
BA_ "VFrameFormat" BO_ 1354 0;
BA_ "CANFD_BRS" BO_ 1354 1;
BA_ "GenMsgCycleTime" BO_ 1354 200;
BA_ "GenMsgCycleTimeFast" BO_ 1354 0;
BA_ "GenMsgSendType" BO_ 1354 0;
BA_ "VFrameFormat" BO_ 1354 0;
BA_ "CANFD_BRS" BO_ 1354 1;
BA_ "GenMsgCycleTime" BO_ 1354 200;
BA_ "GenMsgCycleTimeFast" BO_ 1354 0;
BA_ "GenMsgSendType" BO_ 1354 0;
BA_ "VFrameFormat" BO_ 1354 0;
BA_ "CANFD_BRS" BO_ 1354 1;
BA_ "GenMsgCycleTime" BO_ 1354 200;
BA_ "GenMsgCycleTimeFast" BO_ 1354 0;
BA_ "GenMsgSendType" BO_ 1354 0;
BA_ "VFrameFormat" BO_ 1354 0;
BA_ "CANFD_BRS" BO_ 1354 1;
BA_ "GenMsgCycleTime" BO_ 1354 200;
BA_ "GenMsgCycleTimeFast" BO_ 1354 0;
BA_ "GenMsgSendType" BO_ 1354 0;
BA_ "VFrameFormat" BO_ 1354 0;
BA_ "CANFD_BRS" BO_ 1354 1;
BA_ "GenMsgCycleTime" BO_ 1354 200;
BA_ "GenMsgCycleTimeFast" BO_ 1354 0;
BA_ "GenMsgSendType" BO_ 1354 0;
BA_ "VFrameFormat" BO_ 1354 0;
BA_ "CANFD_BRS" BO_ 1354 1;
BA_ "GenMsgCycleTime" BO_ 1343 200;
BA_ "GenMsgCycleTimeFast" BO_ 1343 0;
BA_ "GenMsgSendType" BO_ 1343 0;
BA_ "VFrameFormat" BO_ 1343 0;
BA_ "CANFD_BRS" BO_ 1343 1;
BA_ "GenMsgCycleTime" BO_ 1343 200;
BA_ "GenMsgCycleTimeFast" BO_ 1343 0;
BA_ "GenMsgSendType" BO_ 1343 0;
BA_ "VFrameFormat" BO_ 1343 0;
BA_ "CANFD_BRS" BO_ 1343 1;
BA_ "GenMsgCycleTime" BO_ 1343 200;
BA_ "GenMsgCycleTimeFast" BO_ 1343 0;
BA_ "GenMsgSendType" BO_ 1343 0;
BA_ "VFrameFormat" BO_ 1343 0;
BA_ "CANFD_BRS" BO_ 1343 1;
BA_ "GenMsgCycleTime" BO_ 1343 200;
BA_ "GenMsgCycleTimeFast" BO_ 1343 0;
BA_ "GenMsgSendType" BO_ 1343 0;
BA_ "VFrameFormat" BO_ 1343 0;
BA_ "CANFD_BRS" BO_ 1343 1;
BA_ "GenMsgCycleTime" BO_ 1343 200;
BA_ "GenMsgCycleTimeFast" BO_ 1343 0;
BA_ "GenMsgSendType" BO_ 1343 0;
BA_ "VFrameFormat" BO_ 1343 0;
BA_ "CANFD_BRS" BO_ 1343 1;
BA_ "GenMsgCycleTime" BO_ 1343 200;
BA_ "GenMsgCycleTimeFast" BO_ 1343 0;
BA_ "GenMsgSendType" BO_ 1343 0;
BA_ "VFrameFormat" BO_ 1343 0;
BA_ "CANFD_BRS" BO_ 1343 1;
BA_ "GenMsgCycleTime" BO_ 1188 0;
BA_ "GenMsgCycleTimeFast" BO_ 1188 0;
BA_ "GenMsgSendType" BO_ 1188 1;
BA_ "VFrameFormat" BO_ 1188 14;
BA_ "CANFD_BRS" BO_ 1188 1;
BA_ "GenMsgCycleTime" BO_ 1269 0;
BA_ "GenMsgCycleTimeFast" BO_ 1269 0;
BA_ "GenMsgSendType" BO_ 1269 1;
BA_ "VFrameFormat" BO_ 1269 14;
BA_ "CANFD_BRS" BO_ 1269 1;
BA_ "GenMsgCycleTime" BO_ 1233 0;
BA_ "GenMsgCycleTimeFast" BO_ 1233 0;
BA_ "GenMsgSendType" BO_ 1233 1;
BA_ "VFrameFormat" BO_ 1233 14;
BA_ "CANFD_BRS" BO_ 1233 1;
BA_ "GenMsgCycleTime" BO_ 1238 0;
BA_ "GenMsgCycleTimeFast" BO_ 1238 0;
BA_ "GenMsgSendType" BO_ 1238 1;
BA_ "VFrameFormat" BO_ 1238 14;
BA_ "CANFD_BRS" BO_ 1238 1;
BA_ "GenMsgCycleTime" BO_ 1934 0;
BA_ "GenMsgCycleTimeFast" BO_ 1934 0;
BA_ "GenMsgSendType" BO_ 1934 1;
BA_ "VFrameFormat" BO_ 1934 14;
BA_ "CANFD_BRS" BO_ 1934 1;
BA_ "GenMsgCycleTime" BO_ 1806 0;
BA_ "GenMsgCycleTimeFast" BO_ 1806 0;
BA_ "GenMsgSendType" BO_ 1806 1;
BA_ "VFrameFormat" BO_ 1806 14;
BA_ "CANFD_BRS" BO_ 1806 1;
BA_ "GenMsgCycleTime" BO_ 1854 0;
BA_ "GenMsgCycleTimeFast" BO_ 1854 0;
BA_ "GenMsgSendType" BO_ 1854 1;
BA_ "VFrameFormat" BO_ 1854 14;
BA_ "CANFD_BRS" BO_ 1854 1;
BA_ "GenMsgCycleTime" BO_ 2015 0;
BA_ "GenMsgCycleTimeFast" BO_ 2015 0;
BA_ "GenMsgSendType" BO_ 2015 1;
BA_ "VFrameFormat" BO_ 2015 14;
BA_ "CANFD_BRS" BO_ 2015 1;
BA_ "EventCommandSignal" SG_ 904 CCU_GwMsg_4_CRC 0;
BA_ "GatewayedSignals" SG_ 904 CCU_GwMsg_4_CRC 0;
BA_ "GenSigInactiveValue" SG_ 904 CCU_GwMsg_4_CRC 0;
BA_ "GenSigInvalidValue" SG_ 904 CCU_GwMsg_4_CRC 0;
BA_ "GenSigSendType" SG_ 904 CCU_GwMsg_4_CRC 1;
BA_ "GenSigStartValue" SG_ 904 CCU_GwMsg_4_CRC 0;
BA_ "GenSigTimeoutValue" SG_ 904 CCU_GwMsg_4_CRC 0;
BA_ "Remark" SG_ 904 CCU_GwMsg_4_CRC "";
BA_ "EventCommandSignal" SG_ 904 CCU_GwMsg_4_Counter 0;
BA_ "GatewayedSignals" SG_ 904 CCU_GwMsg_4_Counter 0;
BA_ "GenSigInactiveValue" SG_ 904 CCU_GwMsg_4_Counter 0;
BA_ "GenSigInvalidValue" SG_ 904 CCU_GwMsg_4_Counter 0;
BA_ "GenSigSendType" SG_ 904 CCU_GwMsg_4_Counter 1;
BA_ "GenSigStartValue" SG_ 904 CCU_GwMsg_4_Counter 0;
BA_ "GenSigTimeoutValue" SG_ 904 CCU_GwMsg_4_Counter 0;
BA_ "Remark" SG_ 904 CCU_GwMsg_4_Counter "";
BA_ "EventCommandSignal" SG_ 904 HVAC_RearDefrostSt 0;
BA_ "GatewayedSignals" SG_ 904 HVAC_RearDefrostSt 0;
BA_ "GenSigInactiveValue" SG_ 904 HVAC_RearDefrostSt 0;
BA_ "GenSigInvalidValue" SG_ 904 HVAC_RearDefrostSt 0;
BA_ "GenSigSendType" SG_ 904 HVAC_RearDefrostSt 1;
BA_ "GenSigStartValue" SG_ 904 HVAC_RearDefrostSt 0;
BA_ "GenSigTimeoutValue" SG_ 904 HVAC_RearDefrostSt 0;
BA_ "Remark" SG_ 904 HVAC_RearDefrostSt "";
BA_ "EventCommandSignal" SG_ 904 HVAC_WindExitMode 0;
BA_ "GatewayedSignals" SG_ 904 HVAC_WindExitMode 0;
BA_ "GenSigInactiveValue" SG_ 904 HVAC_WindExitMode 0;
BA_ "GenSigInvalidValue" SG_ 904 HVAC_WindExitMode 0;
BA_ "GenSigSendType" SG_ 904 HVAC_WindExitMode 1;
BA_ "GenSigStartValue" SG_ 904 HVAC_WindExitMode 0;
BA_ "GenSigTimeoutValue" SG_ 904 HVAC_WindExitMode 0;
BA_ "Remark" SG_ 904 HVAC_WindExitMode "";
BA_ "EventCommandSignal" SG_ 904 HVAC_CorrectedExterTemp 0;
BA_ "GatewayedSignals" SG_ 904 HVAC_CorrectedExterTemp 0;
BA_ "GenSigInactiveValue" SG_ 904 HVAC_CorrectedExterTemp 0;
BA_ "GenSigInvalidValue" SG_ 904 HVAC_CorrectedExterTemp 0;
BA_ "GenSigSendType" SG_ 904 HVAC_CorrectedExterTemp 1;
BA_ "GenSigStartValue" SG_ 904 HVAC_CorrectedExterTemp 120;
BA_ "GenSigTimeoutValue" SG_ 904 HVAC_CorrectedExterTemp 120;
BA_ "Remark" SG_ 904 HVAC_CorrectedExterTemp "";
BA_ "EventCommandSignal" SG_ 904 HVAC_CorrectedExterTempVD 0;
BA_ "GatewayedSignals" SG_ 904 HVAC_CorrectedExterTempVD 0;
BA_ "GenSigInactiveValue" SG_ 904 HVAC_CorrectedExterTempVD 0;
BA_ "GenSigInvalidValue" SG_ 904 HVAC_CorrectedExterTempVD 0;
BA_ "GenSigSendType" SG_ 904 HVAC_CorrectedExterTempVD 1;
BA_ "GenSigStartValue" SG_ 904 HVAC_CorrectedExterTempVD 0;
BA_ "GenSigTimeoutValue" SG_ 904 HVAC_CorrectedExterTempVD 0;
BA_ "Remark" SG_ 904 HVAC_CorrectedExterTempVD "";
BA_ "EventCommandSignal" SG_ 904 HVAC_CorrectedCabinTemp 0;
BA_ "GatewayedSignals" SG_ 904 HVAC_CorrectedCabinTemp 0;
BA_ "GenSigInactiveValue" SG_ 904 HVAC_CorrectedCabinTemp 0;
BA_ "GenSigInvalidValue" SG_ 904 HVAC_CorrectedCabinTemp 0;
BA_ "GenSigSendType" SG_ 904 HVAC_CorrectedCabinTemp 1;
BA_ "GenSigStartValue" SG_ 904 HVAC_CorrectedCabinTemp 120;
BA_ "GenSigTimeoutValue" SG_ 904 HVAC_CorrectedCabinTemp 120;
BA_ "Remark" SG_ 904 HVAC_CorrectedCabinTemp "";
BA_ "EventCommandSignal" SG_ 904 HVAC_CorrectedCabinTempVD 0;
BA_ "GatewayedSignals" SG_ 904 HVAC_CorrectedCabinTempVD 0;
BA_ "GenSigInactiveValue" SG_ 904 HVAC_CorrectedCabinTempVD 0;
BA_ "GenSigInvalidValue" SG_ 904 HVAC_CorrectedCabinTempVD 0;
BA_ "GenSigSendType" SG_ 904 HVAC_CorrectedCabinTempVD 1;
BA_ "GenSigStartValue" SG_ 904 HVAC_CorrectedCabinTempVD 0;
BA_ "GenSigTimeoutValue" SG_ 904 HVAC_CorrectedCabinTempVD 0;
BA_ "Remark" SG_ 904 HVAC_CorrectedCabinTempVD "";
BA_ "EventCommandSignal" SG_ 904 WW_FwpFaultSt 0;
BA_ "GatewayedSignals" SG_ 904 WW_FwpFaultSt 0;
BA_ "GenSigInactiveValue" SG_ 904 WW_FwpFaultSt 0;
BA_ "GenSigInvalidValue" SG_ 904 WW_FwpFaultSt 0;
BA_ "GenSigSendType" SG_ 904 WW_FwpFaultSt 1;
BA_ "GenSigStartValue" SG_ 904 WW_FwpFaultSt 0;
BA_ "GenSigTimeoutValue" SG_ 904 WW_FwpFaultSt 0;
BA_ "Remark" SG_ 904 WW_FwpFaultSt "";
BA_ "EventCommandSignal" SG_ 904 WW_RwpFaultSt 0;
BA_ "GatewayedSignals" SG_ 904 WW_RwpFaultSt 0;
BA_ "GenSigInactiveValue" SG_ 904 WW_RwpFaultSt 0;
BA_ "GenSigInvalidValue" SG_ 904 WW_RwpFaultSt 0;
BA_ "GenSigSendType" SG_ 904 WW_RwpFaultSt 1;
BA_ "GenSigStartValue" SG_ 904 WW_RwpFaultSt 0;
BA_ "GenSigTimeoutValue" SG_ 904 WW_RwpFaultSt 0;
BA_ "Remark" SG_ 904 WW_RwpFaultSt "";
BA_ "EventCommandSignal" SG_ 904 WW_FwshFaultSt 0;
BA_ "GatewayedSignals" SG_ 904 WW_FwshFaultSt 0;
BA_ "GenSigInactiveValue" SG_ 904 WW_FwshFaultSt 0;
BA_ "GenSigInvalidValue" SG_ 904 WW_FwshFaultSt 0;
BA_ "GenSigSendType" SG_ 904 WW_FwshFaultSt 1;
BA_ "GenSigStartValue" SG_ 904 WW_FwshFaultSt 0;
BA_ "GenSigTimeoutValue" SG_ 904 WW_FwshFaultSt 0;
BA_ "Remark" SG_ 904 WW_FwshFaultSt "";
BA_ "EventCommandSignal" SG_ 904 WW_RwshFaultSt 0;
BA_ "GatewayedSignals" SG_ 904 WW_RwshFaultSt 0;
BA_ "GenSigInactiveValue" SG_ 904 WW_RwshFaultSt 0;
BA_ "GenSigInvalidValue" SG_ 904 WW_RwshFaultSt 0;
BA_ "GenSigSendType" SG_ 904 WW_RwshFaultSt 1;
BA_ "GenSigStartValue" SG_ 904 WW_RwshFaultSt 0;
BA_ "GenSigTimeoutValue" SG_ 904 WW_RwshFaultSt 0;
BA_ "Remark" SG_ 904 WW_RwshFaultSt "";
BA_ "EventCommandSignal" SG_ 904 WW_FwpAutoModeSt 0;
BA_ "GatewayedSignals" SG_ 904 WW_FwpAutoModeSt 0;
BA_ "GenSigInactiveValue" SG_ 904 WW_FwpAutoModeSt 0;
BA_ "GenSigInvalidValue" SG_ 904 WW_FwpAutoModeSt 0;
BA_ "GenSigSendType" SG_ 904 WW_FwpAutoModeSt 1;
BA_ "GenSigStartValue" SG_ 904 WW_FwpAutoModeSt 0;
BA_ "GenSigTimeoutValue" SG_ 904 WW_FwpAutoModeSt 0;
BA_ "Remark" SG_ 904 WW_FwpAutoModeSt "";
BA_ "EventCommandSignal" SG_ 904 WW_RainFallLevel 0;
BA_ "GatewayedSignals" SG_ 904 WW_RainFallLevel 0;
BA_ "GenSigInactiveValue" SG_ 904 WW_RainFallLevel 0;
BA_ "GenSigInvalidValue" SG_ 904 WW_RainFallLevel 0;
BA_ "GenSigSendType" SG_ 904 WW_RainFallLevel 1;
BA_ "GenSigStartValue" SG_ 904 WW_RainFallLevel 0;
BA_ "GenSigTimeoutValue" SG_ 904 WW_RainFallLevel 0;
BA_ "Remark" SG_ 904 WW_RainFallLevel "";
BA_ "EventCommandSignal" SG_ 904 RLS_LightOnReq 0;
BA_ "GatewayedSignals" SG_ 904 RLS_LightOnReq 0;
BA_ "GenSigInactiveValue" SG_ 904 RLS_LightOnReq 0;
BA_ "GenSigInvalidValue" SG_ 904 RLS_LightOnReq 0;
BA_ "GenSigSendType" SG_ 904 RLS_LightOnReq 1;
BA_ "GenSigStartValue" SG_ 904 RLS_LightOnReq 0;
BA_ "GenSigTimeoutValue" SG_ 904 RLS_LightOnReq 0;
BA_ "Remark" SG_ 904 RLS_LightOnReq "";
BA_ "EventCommandSignal" SG_ 904 RLS_LampOnReqValid 0;
BA_ "GatewayedSignals" SG_ 904 RLS_LampOnReqValid 0;
BA_ "GenSigInactiveValue" SG_ 904 RLS_LampOnReqValid 0;
BA_ "GenSigInvalidValue" SG_ 904 RLS_LampOnReqValid 0;
BA_ "GenSigSendType" SG_ 904 RLS_LampOnReqValid 1;
BA_ "GenSigStartValue" SG_ 904 RLS_LampOnReqValid 0;
BA_ "GenSigTimeoutValue" SG_ 904 RLS_LampOnReqValid 0;
BA_ "Remark" SG_ 904 RLS_LampOnReqValid "";
BA_ "EventCommandSignal" SG_ 904 RLS_WiperSpd 0;
BA_ "GatewayedSignals" SG_ 904 RLS_WiperSpd 0;
BA_ "GenSigInactiveValue" SG_ 904 RLS_WiperSpd 0;
BA_ "GenSigInvalidValue" SG_ 904 RLS_WiperSpd 0;
BA_ "GenSigSendType" SG_ 904 RLS_WiperSpd 1;
BA_ "GenSigStartValue" SG_ 904 RLS_WiperSpd 0;
BA_ "GenSigTimeoutValue" SG_ 904 RLS_WiperSpd 0;
BA_ "Remark" SG_ 904 RLS_WiperSpd "";
BA_ "EventCommandSignal" SG_ 904 RLS_AMBBrightness 0;
BA_ "GatewayedSignals" SG_ 904 RLS_AMBBrightness 0;
BA_ "GenSigInactiveValue" SG_ 904 RLS_AMBBrightness 0;
BA_ "GenSigInvalidValue" SG_ 904 RLS_AMBBrightness 0;
BA_ "GenSigSendType" SG_ 904 RLS_AMBBrightness 1;
BA_ "GenSigStartValue" SG_ 904 RLS_AMBBrightness 16382;
BA_ "GenSigTimeoutValue" SG_ 904 RLS_AMBBrightness 0;
BA_ "Remark" SG_ 904 RLS_AMBBrightness "";
BA_ "EventCommandSignal" SG_ 904 RLS_FWBrightness 0;
BA_ "GatewayedSignals" SG_ 904 RLS_FWBrightness 0;
BA_ "GenSigInactiveValue" SG_ 904 RLS_FWBrightness 0;
BA_ "GenSigInvalidValue" SG_ 904 RLS_FWBrightness 0;
BA_ "GenSigSendType" SG_ 904 RLS_FWBrightness 1;
BA_ "GenSigStartValue" SG_ 904 RLS_FWBrightness 16382;
BA_ "GenSigTimeoutValue" SG_ 904 RLS_FWBrightness 0;
BA_ "Remark" SG_ 904 RLS_FWBrightness "";
BA_ "EventCommandSignal" SG_ 904 RLS_RainfallLevel 0;
BA_ "GatewayedSignals" SG_ 904 RLS_RainfallLevel 0;
BA_ "GenSigInactiveValue" SG_ 904 RLS_RainfallLevel 0;
BA_ "GenSigInvalidValue" SG_ 904 RLS_RainfallLevel 0;
BA_ "GenSigSendType" SG_ 904 RLS_RainfallLevel 1;
BA_ "GenSigStartValue" SG_ 904 RLS_RainfallLevel 14;
BA_ "GenSigTimeoutValue" SG_ 904 RLS_RainfallLevel 0;
BA_ "Remark" SG_ 904 RLS_RainfallLevel "";
BA_ "EventCommandSignal" SG_ 904 RLS_RSErr 0;
BA_ "GatewayedSignals" SG_ 904 RLS_RSErr 0;
BA_ "GenSigInactiveValue" SG_ 904 RLS_RSErr 0;
BA_ "GenSigInvalidValue" SG_ 904 RLS_RSErr 0;
BA_ "GenSigSendType" SG_ 904 RLS_RSErr 1;
BA_ "GenSigStartValue" SG_ 904 RLS_RSErr 0;
BA_ "GenSigTimeoutValue" SG_ 904 RLS_RSErr 0;
BA_ "Remark" SG_ 904 RLS_RSErr "";
BA_ "EventCommandSignal" SG_ 904 RLS_LSErr 0;
BA_ "GatewayedSignals" SG_ 904 RLS_LSErr 0;
BA_ "GenSigInactiveValue" SG_ 904 RLS_LSErr 0;
BA_ "GenSigInvalidValue" SG_ 904 RLS_LSErr 0;
BA_ "GenSigSendType" SG_ 904 RLS_LSErr 1;
BA_ "GenSigStartValue" SG_ 904 RLS_LSErr 0;
BA_ "GenSigTimeoutValue" SG_ 904 RLS_LSErr 0;
BA_ "Remark" SG_ 904 RLS_LSErr "";
BA_ "EventCommandSignal" SG_ 904 PM_AUTHPstState 0;
BA_ "GatewayedSignals" SG_ 904 PM_AUTHPstState 0;
BA_ "GenSigInactiveValue" SG_ 904 PM_AUTHPstState 0;
BA_ "GenSigInvalidValue" SG_ 904 PM_AUTHPstState 0;
BA_ "GenSigSendType" SG_ 904 PM_AUTHPstState 1;
BA_ "GenSigStartValue" SG_ 904 PM_AUTHPstState 0;
BA_ "GenSigTimeoutValue" SG_ 904 PM_AUTHPstState 0;
BA_ "Remark" SG_ 904 PM_AUTHPstState "";
BA_ "EventCommandSignal" SG_ 904 CCU_FuncReq_SentryMod 0;
BA_ "GatewayedSignals" SG_ 904 CCU_FuncReq_SentryMod 0;
BA_ "GenSigInactiveValue" SG_ 904 CCU_FuncReq_SentryMod 0;
BA_ "GenSigInvalidValue" SG_ 904 CCU_FuncReq_SentryMod 0;
BA_ "GenSigSendType" SG_ 904 CCU_FuncReq_SentryMod 1;
BA_ "GenSigStartValue" SG_ 904 CCU_FuncReq_SentryMod 0;
BA_ "GenSigTimeoutValue" SG_ 904 CCU_FuncReq_SentryMod 0;
BA_ "Remark" SG_ 904 CCU_FuncReq_SentryMod "";
BA_ "EventCommandSignal" SG_ 904 RLS_WindShieldHum 0;
BA_ "GatewayedSignals" SG_ 904 RLS_WindShieldHum 0;
BA_ "GenSigInactiveValue" SG_ 904 RLS_WindShieldHum 0;
BA_ "GenSigInvalidValue" SG_ 904 RLS_WindShieldHum 0;
BA_ "GenSigSendType" SG_ 904 RLS_WindShieldHum 1;
BA_ "GenSigStartValue" SG_ 904 RLS_WindShieldHum 0;
BA_ "GenSigTimeoutValue" SG_ 904 RLS_WindShieldHum 0;
BA_ "Remark" SG_ 904 RLS_WindShieldHum "";
BA_ "EventCommandSignal" SG_ 904 RLS_WindShieldTem 0;
BA_ "GatewayedSignals" SG_ 904 RLS_WindShieldTem 0;
BA_ "GenSigInactiveValue" SG_ 904 RLS_WindShieldTem 0;
BA_ "GenSigInvalidValue" SG_ 904 RLS_WindShieldTem 0;
BA_ "GenSigSendType" SG_ 904 RLS_WindShieldTem 1;
BA_ "GenSigStartValue" SG_ 904 RLS_WindShieldTem 254;
BA_ "GenSigTimeoutValue" SG_ 904 RLS_WindShieldTem 0;
BA_ "Remark" SG_ 904 RLS_WindShieldTem "";
BA_ "EventCommandSignal" SG_ 904 RLS_DewPoint 0;
BA_ "GatewayedSignals" SG_ 904 RLS_DewPoint 0;
BA_ "GenSigInactiveValue" SG_ 904 RLS_DewPoint 0;
BA_ "GenSigInvalidValue" SG_ 904 RLS_DewPoint 0;
BA_ "GenSigSendType" SG_ 904 RLS_DewPoint 1;
BA_ "GenSigStartValue" SG_ 904 RLS_DewPoint 254;
BA_ "GenSigTimeoutValue" SG_ 904 RLS_DewPoint 0;
BA_ "Remark" SG_ 904 RLS_DewPoint "";
BA_ "EventCommandSignal" SG_ 904 CCU_ModeSuppressSts 0;
BA_ "GatewayedSignals" SG_ 904 CCU_ModeSuppressSts 0;
BA_ "GenSigInactiveValue" SG_ 904 CCU_ModeSuppressSts 0;
BA_ "GenSigInvalidValue" SG_ 904 CCU_ModeSuppressSts 0;
BA_ "GenSigSendType" SG_ 904 CCU_ModeSuppressSts 1;
BA_ "GenSigStartValue" SG_ 904 CCU_ModeSuppressSts 0;
BA_ "GenSigTimeoutValue" SG_ 904 CCU_ModeSuppressSts 0;
BA_ "Remark" SG_ 904 CCU_ModeSuppressSts "";
BA_ "EventCommandSignal" SG_ 904 RLS_HUTErr 0;
BA_ "GatewayedSignals" SG_ 904 RLS_HUTErr 0;
BA_ "GenSigInactiveValue" SG_ 904 RLS_HUTErr 0;
BA_ "GenSigInvalidValue" SG_ 904 RLS_HUTErr 0;
BA_ "GenSigSendType" SG_ 904 RLS_HUTErr 1;
BA_ "GenSigStartValue" SG_ 904 RLS_HUTErr 0;
BA_ "GenSigTimeoutValue" SG_ 904 RLS_HUTErr 0;
BA_ "Remark" SG_ 904 RLS_HUTErr "";
BA_ "EventCommandSignal" SG_ 904 SR_SunroofCurrentPst 0;
BA_ "GatewayedSignals" SG_ 904 SR_SunroofCurrentPst 0;
BA_ "GenSigInactiveValue" SG_ 904 SR_SunroofCurrentPst 0;
BA_ "GenSigInvalidValue" SG_ 904 SR_SunroofCurrentPst 0;
BA_ "GenSigSendType" SG_ 904 SR_SunroofCurrentPst 1;
BA_ "GenSigStartValue" SG_ 904 SR_SunroofCurrentPst 255;
BA_ "GenSigTimeoutValue" SG_ 904 SR_SunroofCurrentPst 0;
BA_ "Remark" SG_ 904 SR_SunroofCurrentPst "";
BA_ "EventCommandSignal" SG_ 904 EL_LeftBSDIndicatorSt 0;
BA_ "GatewayedSignals" SG_ 904 EL_LeftBSDIndicatorSt 0;
BA_ "GenSigInactiveValue" SG_ 904 EL_LeftBSDIndicatorSt 0;
BA_ "GenSigInvalidValue" SG_ 904 EL_LeftBSDIndicatorSt 0;
BA_ "GenSigSendType" SG_ 904 EL_LeftBSDIndicatorSt 1;
BA_ "GenSigStartValue" SG_ 904 EL_LeftBSDIndicatorSt 0;
BA_ "GenSigTimeoutValue" SG_ 904 EL_LeftBSDIndicatorSt 0;
BA_ "Remark" SG_ 904 EL_LeftBSDIndicatorSt "";
BA_ "EventCommandSignal" SG_ 904 UINM_HazardLightSwSt 0;
BA_ "GatewayedSignals" SG_ 904 UINM_HazardLightSwSt 0;
BA_ "GenSigInactiveValue" SG_ 904 UINM_HazardLightSwSt 0;
BA_ "GenSigInvalidValue" SG_ 904 UINM_HazardLightSwSt 0;
BA_ "GenSigSendType" SG_ 904 UINM_HazardLightSwSt 1;
BA_ "GenSigStartValue" SG_ 904 UINM_HazardLightSwSt 0;
BA_ "GenSigTimeoutValue" SG_ 904 UINM_HazardLightSwSt 0;
BA_ "Remark" SG_ 904 UINM_HazardLightSwSt "";
BA_ "EventCommandSignal" SG_ 904 EL_MLTurnLightSt 0;
BA_ "GatewayedSignals" SG_ 904 EL_MLTurnLightSt 0;
BA_ "GenSigInactiveValue" SG_ 904 EL_MLTurnLightSt 0;
BA_ "GenSigInvalidValue" SG_ 904 EL_MLTurnLightSt 0;
BA_ "GenSigSendType" SG_ 904 EL_MLTurnLightSt 1;
BA_ "GenSigStartValue" SG_ 904 EL_MLTurnLightSt 0;
BA_ "GenSigTimeoutValue" SG_ 904 EL_MLTurnLightSt 0;
BA_ "Remark" SG_ 904 EL_MLTurnLightSt "";
BA_ "EventCommandSignal" SG_ 904 EL_MLTurnLightFaultSt 0;
BA_ "GatewayedSignals" SG_ 904 EL_MLTurnLightFaultSt 0;
BA_ "GenSigInactiveValue" SG_ 904 EL_MLTurnLightFaultSt 0;
BA_ "GenSigInvalidValue" SG_ 904 EL_MLTurnLightFaultSt 0;
BA_ "GenSigSendType" SG_ 904 EL_MLTurnLightFaultSt 1;
BA_ "GenSigStartValue" SG_ 904 EL_MLTurnLightFaultSt 0;
BA_ "GenSigTimeoutValue" SG_ 904 EL_MLTurnLightFaultSt 0;
BA_ "Remark" SG_ 904 EL_MLTurnLightFaultSt "";
BA_ "EventCommandSignal" SG_ 904 EL_LeftBSDIndicatorFaultSt 0;
BA_ "GatewayedSignals" SG_ 904 EL_LeftBSDIndicatorFaultSt 0;
BA_ "GenSigInactiveValue" SG_ 904 EL_LeftBSDIndicatorFaultSt 0;
BA_ "GenSigInvalidValue" SG_ 904 EL_LeftBSDIndicatorFaultSt 0;
BA_ "GenSigSendType" SG_ 904 EL_LeftBSDIndicatorFaultSt 1;
BA_ "GenSigStartValue" SG_ 904 EL_LeftBSDIndicatorFaultSt 0;
BA_ "GenSigTimeoutValue" SG_ 904 EL_LeftBSDIndicatorFaultSt 0;
BA_ "Remark" SG_ 904 EL_LeftBSDIndicatorFaultSt "";
BA_ "EventCommandSignal" SG_ 904 ZCUL_FrtWindshildHeatSt 0;
BA_ "GatewayedSignals" SG_ 904 ZCUL_FrtWindshildHeatSt 0;
BA_ "GenSigInactiveValue" SG_ 904 ZCUL_FrtWindshildHeatSt 0;
BA_ "GenSigInvalidValue" SG_ 904 ZCUL_FrtWindshildHeatSt 0;
BA_ "GenSigSendType" SG_ 904 ZCUL_FrtWindshildHeatSt 1;
BA_ "GenSigStartValue" SG_ 904 ZCUL_FrtWindshildHeatSt 0;
BA_ "GenSigTimeoutValue" SG_ 904 ZCUL_FrtWindshildHeatSt 0;
BA_ "Remark" SG_ 904 ZCUL_FrtWindshildHeatSt "";
BA_ "EventCommandSignal" SG_ 904 ACU_PCS_SVM_MODCmd 0;
BA_ "GatewayedSignals" SG_ 904 ACU_PCS_SVM_MODCmd 0;
BA_ "GenSigInactiveValue" SG_ 904 ACU_PCS_SVM_MODCmd 0;
BA_ "GenSigInvalidValue" SG_ 904 ACU_PCS_SVM_MODCmd 0;
BA_ "GenSigSendType" SG_ 904 ACU_PCS_SVM_MODCmd 1;
BA_ "GenSigStartValue" SG_ 904 ACU_PCS_SVM_MODCmd 0;
BA_ "GenSigTimeoutValue" SG_ 904 ACU_PCS_SVM_MODCmd 0;
BA_ "Remark" SG_ 904 ACU_PCS_SVM_MODCmd "";
BA_ "EventCommandSignal" SG_ 904 ACU_HeadLightVirtualSwSt 0;
BA_ "GatewayedSignals" SG_ 904 ACU_HeadLightVirtualSwSt 0;
BA_ "GenSigInactiveValue" SG_ 904 ACU_HeadLightVirtualSwSt 0;
BA_ "GenSigInvalidValue" SG_ 904 ACU_HeadLightVirtualSwSt 0;
BA_ "GenSigSendType" SG_ 904 ACU_HeadLightVirtualSwSt 1;
BA_ "GenSigStartValue" SG_ 904 ACU_HeadLightVirtualSwSt 0;
BA_ "GenSigTimeoutValue" SG_ 904 ACU_HeadLightVirtualSwSt 0;
BA_ "Remark" SG_ 904 ACU_HeadLightVirtualSwSt "";
BA_ "EventCommandSignal" SG_ 904 ACU_FrontFogLightVirtualSwSt 0;
BA_ "GatewayedSignals" SG_ 904 ACU_FrontFogLightVirtualSwSt 0;
BA_ "GenSigInactiveValue" SG_ 904 ACU_FrontFogLightVirtualSwSt 0;
BA_ "GenSigInvalidValue" SG_ 904 ACU_FrontFogLightVirtualSwSt 0;
BA_ "GenSigSendType" SG_ 904 ACU_FrontFogLightVirtualSwSt 1;
BA_ "GenSigStartValue" SG_ 904 ACU_FrontFogLightVirtualSwSt 0;
BA_ "GenSigTimeoutValue" SG_ 904 ACU_FrontFogLightVirtualSwSt 0;
BA_ "Remark" SG_ 904 ACU_FrontFogLightVirtualSwSt "";
BA_ "EventCommandSignal" SG_ 904 ACU_RearFogLightVirtualSwSt 0;
BA_ "GatewayedSignals" SG_ 904 ACU_RearFogLightVirtualSwSt 0;
BA_ "GenSigInactiveValue" SG_ 904 ACU_RearFogLightVirtualSwSt 0;
BA_ "GenSigInvalidValue" SG_ 904 ACU_RearFogLightVirtualSwSt 0;
BA_ "GenSigSendType" SG_ 904 ACU_RearFogLightVirtualSwSt 1;
BA_ "GenSigStartValue" SG_ 904 ACU_RearFogLightVirtualSwSt 0;
BA_ "GenSigTimeoutValue" SG_ 904 ACU_RearFogLightVirtualSwSt 0;
BA_ "Remark" SG_ 904 ACU_RearFogLightVirtualSwSt "";
BA_ "EventCommandSignal" SG_ 904 ACU_Account_Uid 0;
BA_ "GatewayedSignals" SG_ 904 ACU_Account_Uid 0;
BA_ "GenSigInactiveValue" SG_ 904 ACU_Account_Uid 0;
BA_ "GenSigInvalidValue" SG_ 904 ACU_Account_Uid 0;
BA_ "GenSigSendType" SG_ 904 ACU_Account_Uid 1;
BA_ "GenSigStartValue" SG_ 904 ACU_Account_Uid 0;
BA_ "GenSigTimeoutValue" SG_ 904 ACU_Account_Uid 0;
BA_ "Remark" SG_ 904 ACU_Account_Uid "";
BA_ "EventCommandSignal" SG_ 904 ACU_IHBC_SwitchReq 0;
BA_ "GatewayedSignals" SG_ 904 ACU_IHBC_SwitchReq 0;
BA_ "GenSigInactiveValue" SG_ 904 ACU_IHBC_SwitchReq 0;
BA_ "GenSigInvalidValue" SG_ 904 ACU_IHBC_SwitchReq 0;
BA_ "GenSigSendType" SG_ 904 ACU_IHBC_SwitchReq 1;
BA_ "GenSigStartValue" SG_ 904 ACU_IHBC_SwitchReq 0;
BA_ "GenSigTimeoutValue" SG_ 904 ACU_IHBC_SwitchReq 0;
BA_ "Remark" SG_ 904 ACU_IHBC_SwitchReq "";
BA_ "EventCommandSignal" SG_ 904 ACU_NDASwitchReq 0;
BA_ "GatewayedSignals" SG_ 904 ACU_NDASwitchReq 0;
BA_ "GenSigInactiveValue" SG_ 904 ACU_NDASwitchReq 0;
BA_ "GenSigInvalidValue" SG_ 904 ACU_NDASwitchReq 0;
BA_ "GenSigSendType" SG_ 904 ACU_NDASwitchReq 1;
BA_ "GenSigStartValue" SG_ 904 ACU_NDASwitchReq 0;
BA_ "GenSigTimeoutValue" SG_ 904 ACU_NDASwitchReq 0;
BA_ "Remark" SG_ 904 ACU_NDASwitchReq "";
BA_ "EventCommandSignal" SG_ 904 ACU_NDALCConSwitchReq 0;
BA_ "GatewayedSignals" SG_ 904 ACU_NDALCConSwitchReq 0;
BA_ "GenSigInactiveValue" SG_ 904 ACU_NDALCConSwitchReq 0;
BA_ "GenSigInvalidValue" SG_ 904 ACU_NDALCConSwitchReq 0;
BA_ "GenSigSendType" SG_ 904 ACU_NDALCConSwitchReq 1;
BA_ "GenSigStartValue" SG_ 904 ACU_NDALCConSwitchReq 0;
BA_ "GenSigTimeoutValue" SG_ 904 ACU_NDALCConSwitchReq 0;
BA_ "Remark" SG_ 904 ACU_NDALCConSwitchReq "";
BA_ "EventCommandSignal" SG_ 904 ACU_NDALCStySwitchReq 0;
BA_ "GatewayedSignals" SG_ 904 ACU_NDALCStySwitchReq 0;
BA_ "GenSigInactiveValue" SG_ 904 ACU_NDALCStySwitchReq 0;
BA_ "GenSigInvalidValue" SG_ 904 ACU_NDALCStySwitchReq 0;
BA_ "GenSigSendType" SG_ 904 ACU_NDALCStySwitchReq 1;
BA_ "GenSigStartValue" SG_ 904 ACU_NDALCStySwitchReq 0;
BA_ "GenSigTimeoutValue" SG_ 904 ACU_NDALCStySwitchReq 0;
BA_ "Remark" SG_ 904 ACU_NDALCStySwitchReq "";
BA_ "EventCommandSignal" SG_ 904 ACU_ADASWarnTypeSwitch 0;
BA_ "GatewayedSignals" SG_ 904 ACU_ADASWarnTypeSwitch 0;
BA_ "GenSigInactiveValue" SG_ 904 ACU_ADASWarnTypeSwitch 0;
BA_ "GenSigInvalidValue" SG_ 904 ACU_ADASWarnTypeSwitch 0;
BA_ "GenSigSendType" SG_ 904 ACU_ADASWarnTypeSwitch 1;
BA_ "GenSigStartValue" SG_ 904 ACU_ADASWarnTypeSwitch 0;
BA_ "GenSigTimeoutValue" SG_ 904 ACU_ADASWarnTypeSwitch 0;
BA_ "Remark" SG_ 904 ACU_ADASWarnTypeSwitch "";
BA_ "EventCommandSignal" SG_ 904 ACU_iACC_StyleConfirmSwitchReq 0;
BA_ "GatewayedSignals" SG_ 904 ACU_iACC_StyleConfirmSwitchReq 0;
BA_ "GenSigInactiveValue" SG_ 904 ACU_iACC_StyleConfirmSwitchReq 0;
BA_ "GenSigInvalidValue" SG_ 904 ACU_iACC_StyleConfirmSwitchReq 0;
BA_ "GenSigSendType" SG_ 904 ACU_iACC_StyleConfirmSwitchReq 1;
BA_ "GenSigStartValue" SG_ 904 ACU_iACC_StyleConfirmSwitchReq 3;
BA_ "GenSigTimeoutValue" SG_ 904 ACU_iACC_StyleConfirmSwitchReq 0;
BA_ "Remark" SG_ 904 ACU_iACC_StyleConfirmSwitchReq "";
BA_ "EventCommandSignal" SG_ 904 ACU_IFC_SpeedLimit 0;
BA_ "GatewayedSignals" SG_ 904 ACU_IFC_SpeedLimit 0;
BA_ "GenSigInactiveValue" SG_ 904 ACU_IFC_SpeedLimit 0;
BA_ "GenSigInvalidValue" SG_ 904 ACU_IFC_SpeedLimit 0;
BA_ "GenSigSendType" SG_ 904 ACU_IFC_SpeedLimit 1;
BA_ "GenSigStartValue" SG_ 904 ACU_IFC_SpeedLimit 0;
BA_ "GenSigTimeoutValue" SG_ 904 ACU_IFC_SpeedLimit 0;
BA_ "Remark" SG_ 904 ACU_IFC_SpeedLimit "";
BA_ "EventCommandSignal" SG_ 904 ACU_IFC_ISDRestOfdis 0;
BA_ "GatewayedSignals" SG_ 904 ACU_IFC_ISDRestOfdis 0;
BA_ "GenSigInactiveValue" SG_ 904 ACU_IFC_ISDRestOfdis 0;
BA_ "GenSigInvalidValue" SG_ 904 ACU_IFC_ISDRestOfdis 0;
BA_ "GenSigSendType" SG_ 904 ACU_IFC_ISDRestOfdis 1;
BA_ "GenSigStartValue" SG_ 904 ACU_IFC_ISDRestOfdis 0;
BA_ "GenSigTimeoutValue" SG_ 904 ACU_IFC_ISDRestOfdis 0;
BA_ "Remark" SG_ 904 ACU_IFC_ISDRestOfdis "";
BA_ "EventCommandSignal" SG_ 904 EL_MLADASLightSt 0;
BA_ "GatewayedSignals" SG_ 904 EL_MLADASLightSt 0;
BA_ "GenSigInactiveValue" SG_ 904 EL_MLADASLightSt 0;
BA_ "GenSigInvalidValue" SG_ 904 EL_MLADASLightSt 0;
BA_ "GenSigSendType" SG_ 904 EL_MLADASLightSt 1;
BA_ "GenSigStartValue" SG_ 904 EL_MLADASLightSt 0;
BA_ "GenSigTimeoutValue" SG_ 904 EL_MLADASLightSt 0;
BA_ "Remark" SG_ 904 EL_MLADASLightSt "";
BA_ "EventCommandSignal" SG_ 904 ACU_IFC_SpeedLimitUnit 0;
BA_ "GatewayedSignals" SG_ 904 ACU_IFC_SpeedLimitUnit 0;
BA_ "GenSigInactiveValue" SG_ 904 ACU_IFC_SpeedLimitUnit 0;
BA_ "GenSigInvalidValue" SG_ 904 ACU_IFC_SpeedLimitUnit 0;
BA_ "GenSigSendType" SG_ 904 ACU_IFC_SpeedLimitUnit 1;
BA_ "GenSigStartValue" SG_ 904 ACU_IFC_SpeedLimitUnit 0;
BA_ "GenSigTimeoutValue" SG_ 904 ACU_IFC_SpeedLimitUnit 1;
BA_ "Remark" SG_ 904 ACU_IFC_SpeedLimitUnit "";
BA_ "EventCommandSignal" SG_ 904 ACU_ThemeType 0;
BA_ "GatewayedSignals" SG_ 904 ACU_ThemeType 0;
BA_ "GenSigInactiveValue" SG_ 904 ACU_ThemeType 0;
BA_ "GenSigInvalidValue" SG_ 904 ACU_ThemeType 0;
BA_ "GenSigSendType" SG_ 904 ACU_ThemeType 1;
BA_ "GenSigStartValue" SG_ 904 ACU_ThemeType 0;
BA_ "GenSigTimeoutValue" SG_ 904 ACU_ThemeType 0;
BA_ "Remark" SG_ 904 ACU_ThemeType "";
BA_ "EventCommandSignal" SG_ 904 ACU_IFC_SpeedLimtType 0;
BA_ "GatewayedSignals" SG_ 904 ACU_IFC_SpeedLimtType 0;
BA_ "GenSigInactiveValue" SG_ 904 ACU_IFC_SpeedLimtType 0;
BA_ "GenSigInvalidValue" SG_ 904 ACU_IFC_SpeedLimtType 0;
BA_ "GenSigSendType" SG_ 904 ACU_IFC_SpeedLimtType 1;
BA_ "GenSigStartValue" SG_ 904 ACU_IFC_SpeedLimtType 0;
BA_ "GenSigTimeoutValue" SG_ 904 ACU_IFC_SpeedLimtType 0;
BA_ "Remark" SG_ 904 ACU_IFC_SpeedLimtType "";
BA_ "EventCommandSignal" SG_ 904 ACU_IFC_RoadType 0;
BA_ "GatewayedSignals" SG_ 904 ACU_IFC_RoadType 0;
BA_ "GenSigInactiveValue" SG_ 904 ACU_IFC_RoadType 0;
BA_ "GenSigInvalidValue" SG_ 904 ACU_IFC_RoadType 0;
BA_ "GenSigSendType" SG_ 904 ACU_IFC_RoadType 1;
BA_ "GenSigStartValue" SG_ 904 ACU_IFC_RoadType 0;
BA_ "GenSigTimeoutValue" SG_ 904 ACU_IFC_RoadType 0;
BA_ "Remark" SG_ 904 ACU_IFC_RoadType "";
BA_ "EventCommandSignal" SG_ 904 ACU_IFC_ZoneCode 0;
BA_ "GatewayedSignals" SG_ 904 ACU_IFC_ZoneCode 0;
BA_ "GenSigInactiveValue" SG_ 904 ACU_IFC_ZoneCode 0;
BA_ "GenSigInvalidValue" SG_ 904 ACU_IFC_ZoneCode 0;
BA_ "GenSigSendType" SG_ 904 ACU_IFC_ZoneCode 1;
BA_ "GenSigStartValue" SG_ 904 ACU_IFC_ZoneCode 0;
BA_ "GenSigTimeoutValue" SG_ 904 ACU_IFC_ZoneCode 1;
BA_ "Remark" SG_ 904 ACU_IFC_ZoneCode "";
BA_ "EventCommandSignal" SG_ 904 ACU_IFC_NaviSt 0;
BA_ "GatewayedSignals" SG_ 904 ACU_IFC_NaviSt 0;
BA_ "GenSigInactiveValue" SG_ 904 ACU_IFC_NaviSt 0;
BA_ "GenSigInvalidValue" SG_ 904 ACU_IFC_NaviSt 0;
BA_ "GenSigSendType" SG_ 904 ACU_IFC_NaviSt 1;
BA_ "GenSigStartValue" SG_ 904 ACU_IFC_NaviSt 0;
BA_ "GenSigTimeoutValue" SG_ 904 ACU_IFC_NaviSt 0;
BA_ "Remark" SG_ 904 ACU_IFC_NaviSt "";
BA_ "EventCommandSignal" SG_ 904 ACU_IFC_NaviCorp 0;
BA_ "GatewayedSignals" SG_ 904 ACU_IFC_NaviCorp 0;
BA_ "GenSigInactiveValue" SG_ 904 ACU_IFC_NaviCorp 0;
BA_ "GenSigInvalidValue" SG_ 904 ACU_IFC_NaviCorp 0;
BA_ "GenSigSendType" SG_ 904 ACU_IFC_NaviCorp 1;
BA_ "GenSigStartValue" SG_ 904 ACU_IFC_NaviCorp 0;
BA_ "GenSigTimeoutValue" SG_ 904 ACU_IFC_NaviCorp 0;
BA_ "Remark" SG_ 904 ACU_IFC_NaviCorp "";
BA_ "EventCommandSignal" SG_ 904 ACU_IFC_NaviNewIconDis 0;
BA_ "GatewayedSignals" SG_ 904 ACU_IFC_NaviNewIconDis 0;
BA_ "GenSigInactiveValue" SG_ 904 ACU_IFC_NaviNewIconDis 0;
BA_ "GenSigInvalidValue" SG_ 904 ACU_IFC_NaviNewIconDis 0;
BA_ "GenSigSendType" SG_ 904 ACU_IFC_NaviNewIconDis 1;
BA_ "GenSigStartValue" SG_ 904 ACU_IFC_NaviNewIconDis 0;
BA_ "GenSigTimeoutValue" SG_ 904 ACU_IFC_NaviNewIconDis 0;
BA_ "Remark" SG_ 904 ACU_IFC_NaviNewIconDis "";
BA_ "EventCommandSignal" SG_ 904 ACU_IFC_OfframpSt 0;
BA_ "GatewayedSignals" SG_ 904 ACU_IFC_OfframpSt 0;
BA_ "GenSigInactiveValue" SG_ 904 ACU_IFC_OfframpSt 0;
BA_ "GenSigInvalidValue" SG_ 904 ACU_IFC_OfframpSt 0;
BA_ "GenSigSendType" SG_ 904 ACU_IFC_OfframpSt 1;
BA_ "GenSigStartValue" SG_ 904 ACU_IFC_OfframpSt 0;
BA_ "GenSigTimeoutValue" SG_ 904 ACU_IFC_OfframpSt 0;
BA_ "Remark" SG_ 904 ACU_IFC_OfframpSt "";
BA_ "EventCommandSignal" SG_ 904 ACU_IFC_NaviNewIcon 0;
BA_ "GatewayedSignals" SG_ 904 ACU_IFC_NaviNewIcon 0;
BA_ "GenSigInactiveValue" SG_ 904 ACU_IFC_NaviNewIcon 0;
BA_ "GenSigInvalidValue" SG_ 904 ACU_IFC_NaviNewIcon 0;
BA_ "GenSigSendType" SG_ 904 ACU_IFC_NaviNewIcon 1;
BA_ "GenSigStartValue" SG_ 904 ACU_IFC_NaviNewIcon 0;
BA_ "GenSigTimeoutValue" SG_ 904 ACU_IFC_NaviNewIcon 0;
BA_ "Remark" SG_ 904 ACU_IFC_NaviNewIcon "";
BA_ "EventCommandSignal" SG_ 904 ACU_IFC_SLCAheadDis 0;
BA_ "GatewayedSignals" SG_ 904 ACU_IFC_SLCAheadDis 0;
BA_ "GenSigInactiveValue" SG_ 904 ACU_IFC_SLCAheadDis 0;
BA_ "GenSigInvalidValue" SG_ 904 ACU_IFC_SLCAheadDis 0;
BA_ "GenSigSendType" SG_ 904 ACU_IFC_SLCAheadDis 1;
BA_ "GenSigStartValue" SG_ 904 ACU_IFC_SLCAheadDis 0;
BA_ "GenSigTimeoutValue" SG_ 904 ACU_IFC_SLCAheadDis 0;
BA_ "Remark" SG_ 904 ACU_IFC_SLCAheadDis "";
BA_ "EventCommandSignal" SG_ 904 ACU_DVR_Switch 0;
BA_ "GatewayedSignals" SG_ 904 ACU_DVR_Switch 0;
BA_ "GenSigInactiveValue" SG_ 904 ACU_DVR_Switch 0;
BA_ "GenSigInvalidValue" SG_ 904 ACU_DVR_Switch 0;
BA_ "GenSigSendType" SG_ 904 ACU_DVR_Switch 1;
BA_ "GenSigStartValue" SG_ 904 ACU_DVR_Switch 0;
BA_ "GenSigTimeoutValue" SG_ 904 ACU_DVR_Switch 0;
BA_ "Remark" SG_ 904 ACU_DVR_Switch "";
BA_ "EventCommandSignal" SG_ 904 ACU_IFC_OfframpDis 0;
BA_ "GatewayedSignals" SG_ 904 ACU_IFC_OfframpDis 0;
BA_ "GenSigInactiveValue" SG_ 904 ACU_IFC_OfframpDis 0;
BA_ "GenSigInvalidValue" SG_ 904 ACU_IFC_OfframpDis 0;
BA_ "GenSigSendType" SG_ 904 ACU_IFC_OfframpDis 1;
BA_ "GenSigStartValue" SG_ 904 ACU_IFC_OfframpDis 254;
BA_ "GenSigTimeoutValue" SG_ 904 ACU_IFC_OfframpDis 254;
BA_ "Remark" SG_ 904 ACU_IFC_OfframpDis "";
BA_ "EventCommandSignal" SG_ 904 SSW_FLSeatSlideCurrentPst 0;
BA_ "GatewayedSignals" SG_ 904 SSW_FLSeatSlideCurrentPst 0;
BA_ "GenSigInactiveValue" SG_ 904 SSW_FLSeatSlideCurrentPst 0;
BA_ "GenSigInvalidValue" SG_ 904 SSW_FLSeatSlideCurrentPst 0;
BA_ "GenSigSendType" SG_ 904 SSW_FLSeatSlideCurrentPst 1;
BA_ "GenSigStartValue" SG_ 904 SSW_FLSeatSlideCurrentPst 255;
BA_ "GenSigTimeoutValue" SG_ 904 SSW_FLSeatSlideCurrentPst 0;
BA_ "Remark" SG_ 904 SSW_FLSeatSlideCurrentPst "";
BA_ "EventCommandSignal" SG_ 904 SSW_FLSeatHeightCurrentPst 0;
BA_ "GatewayedSignals" SG_ 904 SSW_FLSeatHeightCurrentPst 0;
BA_ "GenSigInactiveValue" SG_ 904 SSW_FLSeatHeightCurrentPst 0;
BA_ "GenSigInvalidValue" SG_ 904 SSW_FLSeatHeightCurrentPst 0;
BA_ "GenSigSendType" SG_ 904 SSW_FLSeatHeightCurrentPst 1;
BA_ "GenSigStartValue" SG_ 904 SSW_FLSeatHeightCurrentPst 255;
BA_ "GenSigTimeoutValue" SG_ 904 SSW_FLSeatHeightCurrentPst 0;
BA_ "Remark" SG_ 904 SSW_FLSeatHeightCurrentPst "";
BA_ "EventCommandSignal" SG_ 904 SSW_FLSeatBackrestCurrentPst 0;
BA_ "GatewayedSignals" SG_ 904 SSW_FLSeatBackrestCurrentPst 0;
BA_ "GenSigInactiveValue" SG_ 904 SSW_FLSeatBackrestCurrentPst 0;
BA_ "GenSigInvalidValue" SG_ 904 SSW_FLSeatBackrestCurrentPst 0;
BA_ "GenSigSendType" SG_ 904 SSW_FLSeatBackrestCurrentPst 1;
BA_ "GenSigStartValue" SG_ 904 SSW_FLSeatBackrestCurrentPst 255;
BA_ "GenSigTimeoutValue" SG_ 904 SSW_FLSeatBackrestCurrentPst 0;
BA_ "Remark" SG_ 904 SSW_FLSeatBackrestCurrentPst "";
BA_ "EventCommandSignal" SG_ 904 DrvrSideMotResp 0;
BA_ "GatewayedSignals" SG_ 904 DrvrSideMotResp 0;
BA_ "GenSigInactiveValue" SG_ 904 DrvrSideMotResp 0;
BA_ "GenSigInvalidValue" SG_ 904 DrvrSideMotResp 0;
BA_ "GenSigSendType" SG_ 904 DrvrSideMotResp 1;
BA_ "GenSigStartValue" SG_ 904 DrvrSideMotResp 0;
BA_ "GenSigTimeoutValue" SG_ 904 DrvrSideMotResp 15;
BA_ "Remark" SG_ 904 DrvrSideMotResp "";
BA_ "EventCommandSignal" SG_ 904 EL_LeftLowBeamSt 0;
BA_ "GatewayedSignals" SG_ 904 EL_LeftLowBeamSt 0;
BA_ "GenSigInactiveValue" SG_ 904 EL_LeftLowBeamSt 0;
BA_ "GenSigInvalidValue" SG_ 904 EL_LeftLowBeamSt 0;
BA_ "GenSigSendType" SG_ 904 EL_LeftLowBeamSt 1;
BA_ "GenSigStartValue" SG_ 904 EL_LeftLowBeamSt 0;
BA_ "GenSigTimeoutValue" SG_ 904 EL_LeftLowBeamSt 0;
BA_ "Remark" SG_ 904 EL_LeftLowBeamSt "";
BA_ "EventCommandSignal" SG_ 904 EL_LeftLowBeamFaultSt 0;
BA_ "GatewayedSignals" SG_ 904 EL_LeftLowBeamFaultSt 0;
BA_ "GenSigInactiveValue" SG_ 904 EL_LeftLowBeamFaultSt 0;
BA_ "GenSigInvalidValue" SG_ 904 EL_LeftLowBeamFaultSt 0;
BA_ "GenSigSendType" SG_ 904 EL_LeftLowBeamFaultSt 1;
BA_ "GenSigStartValue" SG_ 904 EL_LeftLowBeamFaultSt 0;
BA_ "GenSigTimeoutValue" SG_ 904 EL_LeftLowBeamFaultSt 0;
BA_ "Remark" SG_ 904 EL_LeftLowBeamFaultSt "";
BA_ "EventCommandSignal" SG_ 904 EL_RightLowBeamSt 0;
BA_ "GatewayedSignals" SG_ 904 EL_RightLowBeamSt 0;
BA_ "GenSigInactiveValue" SG_ 904 EL_RightLowBeamSt 0;
BA_ "GenSigInvalidValue" SG_ 904 EL_RightLowBeamSt 0;
BA_ "GenSigSendType" SG_ 904 EL_RightLowBeamSt 1;
BA_ "GenSigStartValue" SG_ 904 EL_RightLowBeamSt 0;
BA_ "GenSigTimeoutValue" SG_ 904 EL_RightLowBeamSt 0;
BA_ "Remark" SG_ 904 EL_RightLowBeamSt "";
BA_ "EventCommandSignal" SG_ 904 EL_RightLowBeamFaultSt 0;
BA_ "GatewayedSignals" SG_ 904 EL_RightLowBeamFaultSt 0;
BA_ "GenSigInactiveValue" SG_ 904 EL_RightLowBeamFaultSt 0;
BA_ "GenSigInvalidValue" SG_ 904 EL_RightLowBeamFaultSt 0;
BA_ "GenSigSendType" SG_ 904 EL_RightLowBeamFaultSt 1;
BA_ "GenSigStartValue" SG_ 904 EL_RightLowBeamFaultSt 0;
BA_ "GenSigTimeoutValue" SG_ 904 EL_RightLowBeamFaultSt 0;
BA_ "Remark" SG_ 904 EL_RightLowBeamFaultSt "";
BA_ "EventCommandSignal" SG_ 904 WW_FWPMotorSt 0;
BA_ "GatewayedSignals" SG_ 904 WW_FWPMotorSt 0;
BA_ "GenSigInactiveValue" SG_ 904 WW_FWPMotorSt 0;
BA_ "GenSigInvalidValue" SG_ 904 WW_FWPMotorSt 0;
BA_ "GenSigSendType" SG_ 904 WW_FWPMotorSt 1;
BA_ "GenSigStartValue" SG_ 904 WW_FWPMotorSt 0;
BA_ "GenSigTimeoutValue" SG_ 904 WW_FWPMotorSt 0;
BA_ "Remark" SG_ 904 WW_FWPMotorSt "";
BA_ "EventCommandSignal" SG_ 904 EL_FLTurnLightSt 0;
BA_ "GatewayedSignals" SG_ 904 EL_FLTurnLightSt 0;
BA_ "GenSigInactiveValue" SG_ 904 EL_FLTurnLightSt 0;
BA_ "GenSigInvalidValue" SG_ 904 EL_FLTurnLightSt 0;
BA_ "GenSigSendType" SG_ 904 EL_FLTurnLightSt 1;
BA_ "GenSigStartValue" SG_ 904 EL_FLTurnLightSt 0;
BA_ "GenSigTimeoutValue" SG_ 904 EL_FLTurnLightSt 0;
BA_ "Remark" SG_ 904 EL_FLTurnLightSt "";
BA_ "EventCommandSignal" SG_ 904 EL_FLTurnLightFaultSt 0;
BA_ "GatewayedSignals" SG_ 904 EL_FLTurnLightFaultSt 0;
BA_ "GenSigInactiveValue" SG_ 904 EL_FLTurnLightFaultSt 0;
BA_ "GenSigInvalidValue" SG_ 904 EL_FLTurnLightFaultSt 0;
BA_ "GenSigSendType" SG_ 904 EL_FLTurnLightFaultSt 1;
BA_ "GenSigStartValue" SG_ 904 EL_FLTurnLightFaultSt 0;
BA_ "GenSigTimeoutValue" SG_ 904 EL_FLTurnLightFaultSt 0;
BA_ "Remark" SG_ 904 EL_FLTurnLightFaultSt "";
BA_ "EventCommandSignal" SG_ 904 EL_FRTurnLightSt 0;
BA_ "GatewayedSignals" SG_ 904 EL_FRTurnLightSt 0;
BA_ "GenSigInactiveValue" SG_ 904 EL_FRTurnLightSt 0;
BA_ "GenSigInvalidValue" SG_ 904 EL_FRTurnLightSt 0;
BA_ "GenSigSendType" SG_ 904 EL_FRTurnLightSt 1;
BA_ "GenSigStartValue" SG_ 904 EL_FRTurnLightSt 0;
BA_ "GenSigTimeoutValue" SG_ 904 EL_FRTurnLightSt 0;
BA_ "Remark" SG_ 904 EL_FRTurnLightSt "";
BA_ "EventCommandSignal" SG_ 904 EL_FRTurnLightFaultSt 0;
BA_ "GatewayedSignals" SG_ 904 EL_FRTurnLightFaultSt 0;
BA_ "GenSigInactiveValue" SG_ 904 EL_FRTurnLightFaultSt 0;
BA_ "GenSigInvalidValue" SG_ 904 EL_FRTurnLightFaultSt 0;
BA_ "GenSigSendType" SG_ 904 EL_FRTurnLightFaultSt 1;
BA_ "GenSigStartValue" SG_ 904 EL_FRTurnLightFaultSt 0;
BA_ "GenSigTimeoutValue" SG_ 904 EL_FRTurnLightFaultSt 0;
BA_ "Remark" SG_ 904 EL_FRTurnLightFaultSt "";
BA_ "EventCommandSignal" SG_ 904 EL_SideBrkLightSt 0;
BA_ "GatewayedSignals" SG_ 904 EL_SideBrkLightSt 0;
BA_ "GenSigInactiveValue" SG_ 904 EL_SideBrkLightSt 0;
BA_ "GenSigInvalidValue" SG_ 904 EL_SideBrkLightSt 0;
BA_ "GenSigSendType" SG_ 904 EL_SideBrkLightSt 1;
BA_ "GenSigStartValue" SG_ 904 EL_SideBrkLightSt 0;
BA_ "GenSigTimeoutValue" SG_ 904 EL_SideBrkLightSt 0;
BA_ "Remark" SG_ 904 EL_SideBrkLightSt "";
BA_ "EventCommandSignal" SG_ 904 EL_SideBrkLightFaultSt 0;
BA_ "GatewayedSignals" SG_ 904 EL_SideBrkLightFaultSt 0;
BA_ "GenSigInactiveValue" SG_ 904 EL_SideBrkLightFaultSt 0;
BA_ "GenSigInvalidValue" SG_ 904 EL_SideBrkLightFaultSt 0;
BA_ "GenSigSendType" SG_ 904 EL_SideBrkLightFaultSt 1;
BA_ "GenSigStartValue" SG_ 904 EL_SideBrkLightFaultSt 0;
BA_ "GenSigTimeoutValue" SG_ 904 EL_SideBrkLightFaultSt 0;
BA_ "Remark" SG_ 904 EL_SideBrkLightFaultSt "";
BA_ "EventCommandSignal" SG_ 904 EL_CHMSLSt 0;
BA_ "GatewayedSignals" SG_ 904 EL_CHMSLSt 0;
BA_ "GenSigInactiveValue" SG_ 904 EL_CHMSLSt 0;
BA_ "GenSigInvalidValue" SG_ 904 EL_CHMSLSt 0;
BA_ "GenSigSendType" SG_ 904 EL_CHMSLSt 1;
BA_ "GenSigStartValue" SG_ 904 EL_CHMSLSt 0;
BA_ "GenSigTimeoutValue" SG_ 904 EL_CHMSLSt 0;
BA_ "Remark" SG_ 904 EL_CHMSLSt "";
BA_ "EventCommandSignal" SG_ 904 EL_CHMSLFaultSt 0;
BA_ "GatewayedSignals" SG_ 904 EL_CHMSLFaultSt 0;
BA_ "GenSigInactiveValue" SG_ 904 EL_CHMSLFaultSt 0;
BA_ "GenSigInvalidValue" SG_ 904 EL_CHMSLFaultSt 0;
BA_ "GenSigSendType" SG_ 904 EL_CHMSLFaultSt 1;
BA_ "GenSigStartValue" SG_ 904 EL_CHMSLFaultSt 0;
BA_ "GenSigTimeoutValue" SG_ 904 EL_CHMSLFaultSt 0;
BA_ "Remark" SG_ 904 EL_CHMSLFaultSt "";
BA_ "EventCommandSignal" SG_ 904 EL_RLTurnLightSt 0;
BA_ "GatewayedSignals" SG_ 904 EL_RLTurnLightSt 0;
BA_ "GenSigInactiveValue" SG_ 904 EL_RLTurnLightSt 0;
BA_ "GenSigInvalidValue" SG_ 904 EL_RLTurnLightSt 0;
BA_ "GenSigSendType" SG_ 904 EL_RLTurnLightSt 1;
BA_ "GenSigStartValue" SG_ 904 EL_RLTurnLightSt 0;
BA_ "GenSigTimeoutValue" SG_ 904 EL_RLTurnLightSt 0;
BA_ "Remark" SG_ 904 EL_RLTurnLightSt "";
BA_ "EventCommandSignal" SG_ 904 EL_RLTurnLightFaultSt 0;
BA_ "GatewayedSignals" SG_ 904 EL_RLTurnLightFaultSt 0;
BA_ "GenSigInactiveValue" SG_ 904 EL_RLTurnLightFaultSt 0;
BA_ "GenSigInvalidValue" SG_ 904 EL_RLTurnLightFaultSt 0;
BA_ "GenSigSendType" SG_ 904 EL_RLTurnLightFaultSt 1;
BA_ "GenSigStartValue" SG_ 904 EL_RLTurnLightFaultSt 0;
BA_ "GenSigTimeoutValue" SG_ 904 EL_RLTurnLightFaultSt 0;
BA_ "Remark" SG_ 904 EL_RLTurnLightFaultSt "";
BA_ "EventCommandSignal" SG_ 904 EL_RRTurnLightSt 0;
BA_ "GatewayedSignals" SG_ 904 EL_RRTurnLightSt 0;
BA_ "GenSigInactiveValue" SG_ 904 EL_RRTurnLightSt 0;
BA_ "GenSigInvalidValue" SG_ 904 EL_RRTurnLightSt 0;
BA_ "GenSigSendType" SG_ 904 EL_RRTurnLightSt 1;
BA_ "GenSigStartValue" SG_ 904 EL_RRTurnLightSt 0;
BA_ "GenSigTimeoutValue" SG_ 904 EL_RRTurnLightSt 0;
BA_ "Remark" SG_ 904 EL_RRTurnLightSt "";
BA_ "EventCommandSignal" SG_ 904 EL_RRTurnLightFaultSt 0;
BA_ "GatewayedSignals" SG_ 904 EL_RRTurnLightFaultSt 0;
BA_ "GenSigInactiveValue" SG_ 904 EL_RRTurnLightFaultSt 0;
BA_ "GenSigInvalidValue" SG_ 904 EL_RRTurnLightFaultSt 0;
BA_ "GenSigSendType" SG_ 904 EL_RRTurnLightFaultSt 1;
BA_ "GenSigStartValue" SG_ 904 EL_RRTurnLightFaultSt 0;
BA_ "GenSigTimeoutValue" SG_ 904 EL_RRTurnLightFaultSt 0;
BA_ "Remark" SG_ 904 EL_RRTurnLightFaultSt "";
BA_ "EventCommandSignal" SG_ 904 IPS_DCDCModeSt 0;
BA_ "GatewayedSignals" SG_ 904 IPS_DCDCModeSt 0;
BA_ "GenSigInactiveValue" SG_ 904 IPS_DCDCModeSt 0;
BA_ "GenSigInvalidValue" SG_ 904 IPS_DCDCModeSt 0;
BA_ "GenSigSendType" SG_ 904 IPS_DCDCModeSt 1;
BA_ "GenSigStartValue" SG_ 904 IPS_DCDCModeSt 0;
BA_ "GenSigTimeoutValue" SG_ 904 IPS_DCDCModeSt 0;
BA_ "Remark" SG_ 904 IPS_DCDCModeSt "";
BA_ "EventCommandSignal" SG_ 904 IPDS_FRRadarPowerSup 0;
BA_ "GatewayedSignals" SG_ 904 IPDS_FRRadarPowerSup 0;
BA_ "GenSigInactiveValue" SG_ 904 IPDS_FRRadarPowerSup 0;
BA_ "GenSigInvalidValue" SG_ 904 IPDS_FRRadarPowerSup 0;
BA_ "GenSigSendType" SG_ 904 IPDS_FRRadarPowerSup 1;
BA_ "GenSigStartValue" SG_ 904 IPDS_FRRadarPowerSup 3;
BA_ "GenSigTimeoutValue" SG_ 904 IPDS_FRRadarPowerSup 0;
BA_ "Remark" SG_ 904 IPDS_FRRadarPowerSup "";
BA_ "EventCommandSignal" SG_ 904 IPDS_FLRadarPowerSup 0;
BA_ "GatewayedSignals" SG_ 904 IPDS_FLRadarPowerSup 0;
BA_ "GenSigInactiveValue" SG_ 904 IPDS_FLRadarPowerSup 0;
BA_ "GenSigInvalidValue" SG_ 904 IPDS_FLRadarPowerSup 0;
BA_ "GenSigSendType" SG_ 904 IPDS_FLRadarPowerSup 1;
BA_ "GenSigStartValue" SG_ 904 IPDS_FLRadarPowerSup 3;
BA_ "GenSigTimeoutValue" SG_ 904 IPDS_FLRadarPowerSup 0;
BA_ "Remark" SG_ 904 IPDS_FLRadarPowerSup "";
BA_ "EventCommandSignal" SG_ 904 IPDS_FrontRadarPowerSup 0;
BA_ "GatewayedSignals" SG_ 904 IPDS_FrontRadarPowerSup 0;
BA_ "GenSigInactiveValue" SG_ 904 IPDS_FrontRadarPowerSup 0;
BA_ "GenSigInvalidValue" SG_ 904 IPDS_FrontRadarPowerSup 0;
BA_ "GenSigSendType" SG_ 904 IPDS_FrontRadarPowerSup 1;
BA_ "GenSigStartValue" SG_ 904 IPDS_FrontRadarPowerSup 3;
BA_ "GenSigTimeoutValue" SG_ 904 IPDS_FrontRadarPowerSup 0;
BA_ "Remark" SG_ 904 IPDS_FrontRadarPowerSup "";
BA_ "EventCommandSignal" SG_ 904 IPDS_HDMapPowerSup 0;
BA_ "GatewayedSignals" SG_ 904 IPDS_HDMapPowerSup 0;
BA_ "GenSigInactiveValue" SG_ 904 IPDS_HDMapPowerSup 0;
BA_ "GenSigInvalidValue" SG_ 904 IPDS_HDMapPowerSup 0;
BA_ "GenSigSendType" SG_ 904 IPDS_HDMapPowerSup 1;
BA_ "GenSigStartValue" SG_ 904 IPDS_HDMapPowerSup 3;
BA_ "GenSigTimeoutValue" SG_ 904 IPDS_HDMapPowerSup 0;
BA_ "Remark" SG_ 904 IPDS_HDMapPowerSup "";
BA_ "EventCommandSignal" SG_ 904 IPDS_RearRadarPowerSup 0;
BA_ "GatewayedSignals" SG_ 904 IPDS_RearRadarPowerSup 0;
BA_ "GenSigInactiveValue" SG_ 904 IPDS_RearRadarPowerSup 0;
BA_ "GenSigInvalidValue" SG_ 904 IPDS_RearRadarPowerSup 0;
BA_ "GenSigSendType" SG_ 904 IPDS_RearRadarPowerSup 1;
BA_ "GenSigStartValue" SG_ 904 IPDS_RearRadarPowerSup 3;
BA_ "GenSigTimeoutValue" SG_ 904 IPDS_RearRadarPowerSup 0;
BA_ "Remark" SG_ 904 IPDS_RearRadarPowerSup "";
BA_ "EventCommandSignal" SG_ 1359 CCU_NMNodeAddress 0;
BA_ "GatewayedSignals" SG_ 1359 CCU_NMNodeAddress 0;
BA_ "GenSigInactiveValue" SG_ 1359 CCU_NMNodeAddress 0;
BA_ "GenSigInvalidValue" SG_ 1359 CCU_NMNodeAddress 0;
BA_ "GenSigSendType" SG_ 1359 CCU_NMNodeAddress 1;
BA_ "GenSigStartValue" SG_ 1359 CCU_NMNodeAddress 79;
BA_ "GenSigTimeoutValue" SG_ 1359 CCU_NMNodeAddress 0;
BA_ "Remark" SG_ 1359 CCU_NMNodeAddress "";
BA_ "EventCommandSignal" SG_ 1359 CCU_NMCBV 0;
BA_ "GatewayedSignals" SG_ 1359 CCU_NMCBV 0;
BA_ "GenSigInactiveValue" SG_ 1359 CCU_NMCBV 0;
BA_ "GenSigInvalidValue" SG_ 1359 CCU_NMCBV 0;
BA_ "GenSigSendType" SG_ 1359 CCU_NMCBV 1;
BA_ "GenSigStartValue" SG_ 1359 CCU_NMCBV 0;
BA_ "GenSigTimeoutValue" SG_ 1359 CCU_NMCBV 0;
BA_ "Remark" SG_ 1359 CCU_NMCBV "";
BA_ "EventCommandSignal" SG_ 1359 CCU_NMWakeupOrigin 0;
BA_ "GatewayedSignals" SG_ 1359 CCU_NMWakeupOrigin 0;
BA_ "GenSigInactiveValue" SG_ 1359 CCU_NMWakeupOrigin 0;
BA_ "GenSigInvalidValue" SG_ 1359 CCU_NMWakeupOrigin 0;
BA_ "GenSigSendType" SG_ 1359 CCU_NMWakeupOrigin 1;
BA_ "GenSigStartValue" SG_ 1359 CCU_NMWakeupOrigin 0;
BA_ "GenSigTimeoutValue" SG_ 1359 CCU_NMWakeupOrigin 0;
BA_ "Remark" SG_ 1359 CCU_NMWakeupOrigin "";
BA_ "EventCommandSignal" SG_ 1359 CCU_PNCInformation0 0;
BA_ "GatewayedSignals" SG_ 1359 CCU_PNCInformation0 0;
BA_ "GenSigInactiveValue" SG_ 1359 CCU_PNCInformation0 0;
BA_ "GenSigInvalidValue" SG_ 1359 CCU_PNCInformation0 0;
BA_ "GenSigSendType" SG_ 1359 CCU_PNCInformation0 1;
BA_ "GenSigStartValue" SG_ 1359 CCU_PNCInformation0 0;
BA_ "GenSigTimeoutValue" SG_ 1359 CCU_PNCInformation0 0;
BA_ "Remark" SG_ 1359 CCU_PNCInformation0 "";
BA_ "EventCommandSignal" SG_ 1359 CCU_PNCInformation1 0;
BA_ "GatewayedSignals" SG_ 1359 CCU_PNCInformation1 0;
BA_ "GenSigInactiveValue" SG_ 1359 CCU_PNCInformation1 0;
BA_ "GenSigInvalidValue" SG_ 1359 CCU_PNCInformation1 0;
BA_ "GenSigSendType" SG_ 1359 CCU_PNCInformation1 1;
BA_ "GenSigStartValue" SG_ 1359 CCU_PNCInformation1 0;
BA_ "GenSigTimeoutValue" SG_ 1359 CCU_PNCInformation1 0;
BA_ "Remark" SG_ 1359 CCU_PNCInformation1 "";
BA_ "EventCommandSignal" SG_ 1359 CCU_PNCInformation2 0;
BA_ "GatewayedSignals" SG_ 1359 CCU_PNCInformation2 0;
BA_ "GenSigInactiveValue" SG_ 1359 CCU_PNCInformation2 0;
BA_ "GenSigInvalidValue" SG_ 1359 CCU_PNCInformation2 0;
BA_ "GenSigSendType" SG_ 1359 CCU_PNCInformation2 1;
BA_ "GenSigStartValue" SG_ 1359 CCU_PNCInformation2 0;
BA_ "GenSigTimeoutValue" SG_ 1359 CCU_PNCInformation2 0;
BA_ "Remark" SG_ 1359 CCU_PNCInformation2 "";
BA_ "EventCommandSignal" SG_ 1294 ADC_NMNodeAddress 0;
BA_ "GatewayedSignals" SG_ 1294 ADC_NMNodeAddress 0;
BA_ "GenSigInactiveValue" SG_ 1294 ADC_NMNodeAddress 0;
BA_ "GenSigInvalidValue" SG_ 1294 ADC_NMNodeAddress 0;
BA_ "GenSigSendType" SG_ 1294 ADC_NMNodeAddress 1;
BA_ "GenSigStartValue" SG_ 1294 ADC_NMNodeAddress 14;
BA_ "GenSigTimeoutValue" SG_ 1294 ADC_NMNodeAddress 0;
BA_ "Remark" SG_ 1294 ADC_NMNodeAddress "";
BA_ "EventCommandSignal" SG_ 1294 ADC_NMCBV 0;
BA_ "GatewayedSignals" SG_ 1294 ADC_NMCBV 0;
BA_ "GenSigInactiveValue" SG_ 1294 ADC_NMCBV 0;
BA_ "GenSigInvalidValue" SG_ 1294 ADC_NMCBV 0;
BA_ "GenSigSendType" SG_ 1294 ADC_NMCBV 1;
BA_ "GenSigStartValue" SG_ 1294 ADC_NMCBV 0;
BA_ "GenSigTimeoutValue" SG_ 1294 ADC_NMCBV 0;
BA_ "Remark" SG_ 1294 ADC_NMCBV "";
BA_ "EventCommandSignal" SG_ 1294 ADC_NMWakeupOrigin 0;
BA_ "GatewayedSignals" SG_ 1294 ADC_NMWakeupOrigin 0;
BA_ "GenSigInactiveValue" SG_ 1294 ADC_NMWakeupOrigin 0;
BA_ "GenSigInvalidValue" SG_ 1294 ADC_NMWakeupOrigin 0;
BA_ "GenSigSendType" SG_ 1294 ADC_NMWakeupOrigin 1;
BA_ "GenSigStartValue" SG_ 1294 ADC_NMWakeupOrigin 0;
BA_ "GenSigTimeoutValue" SG_ 1294 ADC_NMWakeupOrigin 0;
BA_ "Remark" SG_ 1294 ADC_NMWakeupOrigin "";
BA_ "EventCommandSignal" SG_ 1294 ADC_PNCInformation0 0;
BA_ "GatewayedSignals" SG_ 1294 ADC_PNCInformation0 0;
BA_ "GenSigInactiveValue" SG_ 1294 ADC_PNCInformation0 0;
BA_ "GenSigInvalidValue" SG_ 1294 ADC_PNCInformation0 0;
BA_ "GenSigSendType" SG_ 1294 ADC_PNCInformation0 1;
BA_ "GenSigStartValue" SG_ 1294 ADC_PNCInformation0 0;
BA_ "GenSigTimeoutValue" SG_ 1294 ADC_PNCInformation0 0;
BA_ "Remark" SG_ 1294 ADC_PNCInformation0 "";
BA_ "EventCommandSignal" SG_ 1294 ADC_PNCInformation1 0;
BA_ "GatewayedSignals" SG_ 1294 ADC_PNCInformation1 0;
BA_ "GenSigInactiveValue" SG_ 1294 ADC_PNCInformation1 0;
BA_ "GenSigInvalidValue" SG_ 1294 ADC_PNCInformation1 0;
BA_ "GenSigSendType" SG_ 1294 ADC_PNCInformation1 1;
BA_ "GenSigStartValue" SG_ 1294 ADC_PNCInformation1 0;
BA_ "GenSigTimeoutValue" SG_ 1294 ADC_PNCInformation1 0;
BA_ "Remark" SG_ 1294 ADC_PNCInformation1 "";
BA_ "EventCommandSignal" SG_ 1294 ADC_PNCInformation2 0;
BA_ "GatewayedSignals" SG_ 1294 ADC_PNCInformation2 0;
BA_ "GenSigInactiveValue" SG_ 1294 ADC_PNCInformation2 0;
BA_ "GenSigInvalidValue" SG_ 1294 ADC_PNCInformation2 0;
BA_ "GenSigSendType" SG_ 1294 ADC_PNCInformation2 1;
BA_ "GenSigStartValue" SG_ 1294 ADC_PNCInformation2 0;
BA_ "GenSigTimeoutValue" SG_ 1294 ADC_PNCInformation2 0;
BA_ "Remark" SG_ 1294 ADC_PNCInformation2 "";
BA_ "EventCommandSignal" SG_ 1354 RLR_NMNodeAddress 0;
BA_ "GatewayedSignals" SG_ 1354 RLR_NMNodeAddress 0;
BA_ "GenSigInactiveValue" SG_ 1354 RLR_NMNodeAddress 0;
BA_ "GenSigInvalidValue" SG_ 1354 RLR_NMNodeAddress 0;
BA_ "GenSigSendType" SG_ 1354 RLR_NMNodeAddress 1;
BA_ "GenSigStartValue" SG_ 1354 RLR_NMNodeAddress 74;
BA_ "GenSigTimeoutValue" SG_ 1354 RLR_NMNodeAddress 0;
BA_ "Remark" SG_ 1354 RLR_NMNodeAddress "";
BA_ "EventCommandSignal" SG_ 1354 RLR_NMCBV 0;
BA_ "GatewayedSignals" SG_ 1354 RLR_NMCBV 0;
BA_ "GenSigInactiveValue" SG_ 1354 RLR_NMCBV 0;
BA_ "GenSigInvalidValue" SG_ 1354 RLR_NMCBV 0;
BA_ "GenSigSendType" SG_ 1354 RLR_NMCBV 1;
BA_ "GenSigStartValue" SG_ 1354 RLR_NMCBV 0;
BA_ "GenSigTimeoutValue" SG_ 1354 RLR_NMCBV 0;
BA_ "Remark" SG_ 1354 RLR_NMCBV "";
BA_ "EventCommandSignal" SG_ 1354 RLR_NMWakeupOrigin 0;
BA_ "GatewayedSignals" SG_ 1354 RLR_NMWakeupOrigin 0;
BA_ "GenSigInactiveValue" SG_ 1354 RLR_NMWakeupOrigin 0;
BA_ "GenSigInvalidValue" SG_ 1354 RLR_NMWakeupOrigin 0;
BA_ "GenSigSendType" SG_ 1354 RLR_NMWakeupOrigin 1;
BA_ "GenSigStartValue" SG_ 1354 RLR_NMWakeupOrigin 0;
BA_ "GenSigTimeoutValue" SG_ 1354 RLR_NMWakeupOrigin 0;
BA_ "Remark" SG_ 1354 RLR_NMWakeupOrigin "";
BA_ "EventCommandSignal" SG_ 1354 RLR_PNCInformation0 0;
BA_ "GatewayedSignals" SG_ 1354 RLR_PNCInformation0 0;
BA_ "GenSigInactiveValue" SG_ 1354 RLR_PNCInformation0 0;
BA_ "GenSigInvalidValue" SG_ 1354 RLR_PNCInformation0 0;
BA_ "GenSigSendType" SG_ 1354 RLR_PNCInformation0 1;
BA_ "GenSigStartValue" SG_ 1354 RLR_PNCInformation0 0;
BA_ "GenSigTimeoutValue" SG_ 1354 RLR_PNCInformation0 0;
BA_ "Remark" SG_ 1354 RLR_PNCInformation0 "";
BA_ "EventCommandSignal" SG_ 1354 RLR_PNCInformation1 0;
BA_ "GatewayedSignals" SG_ 1354 RLR_PNCInformation1 0;
BA_ "GenSigInactiveValue" SG_ 1354 RLR_PNCInformation1 0;
BA_ "GenSigInvalidValue" SG_ 1354 RLR_PNCInformation1 0;
BA_ "GenSigSendType" SG_ 1354 RLR_PNCInformation1 1;
BA_ "GenSigStartValue" SG_ 1354 RLR_PNCInformation1 0;
BA_ "GenSigTimeoutValue" SG_ 1354 RLR_PNCInformation1 0;
BA_ "Remark" SG_ 1354 RLR_PNCInformation1 "";
BA_ "EventCommandSignal" SG_ 1354 RLR_PNCInformation2 0;
BA_ "GatewayedSignals" SG_ 1354 RLR_PNCInformation2 0;
BA_ "GenSigInactiveValue" SG_ 1354 RLR_PNCInformation2 0;
BA_ "GenSigInvalidValue" SG_ 1354 RLR_PNCInformation2 0;
BA_ "GenSigSendType" SG_ 1354 RLR_PNCInformation2 1;
BA_ "GenSigStartValue" SG_ 1354 RLR_PNCInformation2 0;
BA_ "GenSigTimeoutValue" SG_ 1354 RLR_PNCInformation2 0;
BA_ "Remark" SG_ 1354 RLR_PNCInformation2 "";
BA_ "EventCommandSignal" SG_ 1343 RRR_NMNodeAddress 0;
BA_ "GatewayedSignals" SG_ 1343 RRR_NMNodeAddress 0;
BA_ "GenSigInactiveValue" SG_ 1343 RRR_NMNodeAddress 0;
BA_ "GenSigInvalidValue" SG_ 1343 RRR_NMNodeAddress 0;
BA_ "GenSigSendType" SG_ 1343 RRR_NMNodeAddress 1;
BA_ "GenSigStartValue" SG_ 1343 RRR_NMNodeAddress 63;
BA_ "GenSigTimeoutValue" SG_ 1343 RRR_NMNodeAddress 0;
BA_ "Remark" SG_ 1343 RRR_NMNodeAddress "";
BA_ "EventCommandSignal" SG_ 1343 RRR_NMCBV 0;
BA_ "GatewayedSignals" SG_ 1343 RRR_NMCBV 0;
BA_ "GenSigInactiveValue" SG_ 1343 RRR_NMCBV 0;
BA_ "GenSigInvalidValue" SG_ 1343 RRR_NMCBV 0;
BA_ "GenSigSendType" SG_ 1343 RRR_NMCBV 1;
BA_ "GenSigStartValue" SG_ 1343 RRR_NMCBV 0;
BA_ "GenSigTimeoutValue" SG_ 1343 RRR_NMCBV 0;
BA_ "Remark" SG_ 1343 RRR_NMCBV "";
BA_ "EventCommandSignal" SG_ 1343 RRR_NMWakeupOrigin 0;
BA_ "GatewayedSignals" SG_ 1343 RRR_NMWakeupOrigin 0;
BA_ "GenSigInactiveValue" SG_ 1343 RRR_NMWakeupOrigin 0;
BA_ "GenSigInvalidValue" SG_ 1343 RRR_NMWakeupOrigin 0;
BA_ "GenSigSendType" SG_ 1343 RRR_NMWakeupOrigin 1;
BA_ "GenSigStartValue" SG_ 1343 RRR_NMWakeupOrigin 0;
BA_ "GenSigTimeoutValue" SG_ 1343 RRR_NMWakeupOrigin 0;
BA_ "Remark" SG_ 1343 RRR_NMWakeupOrigin "";
BA_ "EventCommandSignal" SG_ 1343 RRR_PNCInformation0 0;
BA_ "GatewayedSignals" SG_ 1343 RRR_PNCInformation0 0;
BA_ "GenSigInactiveValue" SG_ 1343 RRR_PNCInformation0 0;
BA_ "GenSigInvalidValue" SG_ 1343 RRR_PNCInformation0 0;
BA_ "GenSigSendType" SG_ 1343 RRR_PNCInformation0 1;
BA_ "GenSigStartValue" SG_ 1343 RRR_PNCInformation0 0;
BA_ "GenSigTimeoutValue" SG_ 1343 RRR_PNCInformation0 0;
BA_ "Remark" SG_ 1343 RRR_PNCInformation0 "";
BA_ "EventCommandSignal" SG_ 1343 RRR_PNCInformation1 0;
BA_ "GatewayedSignals" SG_ 1343 RRR_PNCInformation1 0;
BA_ "GenSigInactiveValue" SG_ 1343 RRR_PNCInformation1 0;
BA_ "GenSigInvalidValue" SG_ 1343 RRR_PNCInformation1 0;
BA_ "GenSigSendType" SG_ 1343 RRR_PNCInformation1 1;
BA_ "GenSigStartValue" SG_ 1343 RRR_PNCInformation1 0;
BA_ "GenSigTimeoutValue" SG_ 1343 RRR_PNCInformation1 0;
BA_ "Remark" SG_ 1343 RRR_PNCInformation1 "";
BA_ "EventCommandSignal" SG_ 1343 RRR_PNCInformation2 0;
BA_ "GatewayedSignals" SG_ 1343 RRR_PNCInformation2 0;
BA_ "GenSigInactiveValue" SG_ 1343 RRR_PNCInformation2 0;
BA_ "GenSigInvalidValue" SG_ 1343 RRR_PNCInformation2 0;
BA_ "GenSigSendType" SG_ 1343 RRR_PNCInformation2 1;
BA_ "GenSigStartValue" SG_ 1343 RRR_PNCInformation2 0;
BA_ "GenSigTimeoutValue" SG_ 1343 RRR_PNCInformation2 0;
BA_ "Remark" SG_ 1343 RRR_PNCInformation2 "";
BA_ "EventCommandSignal" SG_ 1188 ADC_DTC 1;
BA_ "GatewayedSignals" SG_ 1188 ADC_DTC 0;
BA_ "GenSigInactiveValue" SG_ 1188 ADC_DTC 0;
BA_ "GenSigInvalidValue" SG_ 1188 ADC_DTC 0;
BA_ "GenSigSendType" SG_ 1188 ADC_DTC 0;
BA_ "GenSigStartValue" SG_ 1188 ADC_DTC 0;
BA_ "GenSigTimeoutValue" SG_ 1188 ADC_DTC 0;
BA_ "Remark" SG_ 1188 ADC_DTC "每两帧的发送间隔时间是1000ms";
BA_ "EventCommandSignal" SG_ 1269 FL_DTCCode 1;
BA_ "GatewayedSignals" SG_ 1269 FL_DTCCode 0;
BA_ "GenSigInactiveValue" SG_ 1269 FL_DTCCode 0;
BA_ "GenSigInvalidValue" SG_ 1269 FL_DTCCode 0;
BA_ "GenSigSendType" SG_ 1269 FL_DTCCode 0;
BA_ "GenSigStartValue" SG_ 1269 FL_DTCCode 0;
BA_ "GenSigTimeoutValue" SG_ 1269 FL_DTCCode 0;
BA_ "Remark" SG_ 1269 FL_DTCCode "";
BA_ "EventCommandSignal" SG_ 1233 INU_DTCCode 1;
BA_ "GatewayedSignals" SG_ 1233 INU_DTCCode 0;
BA_ "GenSigInactiveValue" SG_ 1233 INU_DTCCode 0;
BA_ "GenSigInvalidValue" SG_ 1233 INU_DTCCode 0;
BA_ "GenSigSendType" SG_ 1233 INU_DTCCode 0;
BA_ "GenSigStartValue" SG_ 1233 INU_DTCCode 0;
BA_ "GenSigTimeoutValue" SG_ 1233 INU_DTCCode 0;
BA_ "Remark" SG_ 1233 INU_DTCCode "";
BA_ "EventCommandSignal" SG_ 1238 FR_DTCCode 1;
BA_ "GatewayedSignals" SG_ 1238 FR_DTCCode 0;
BA_ "GenSigInactiveValue" SG_ 1238 FR_DTCCode 0;
BA_ "GenSigInvalidValue" SG_ 1238 FR_DTCCode 0;
BA_ "GenSigSendType" SG_ 1238 FR_DTCCode 0;
BA_ "GenSigStartValue" SG_ 1238 FR_DTCCode 0;
BA_ "GenSigTimeoutValue" SG_ 1238 FR_DTCCode 0;
BA_ "Remark" SG_ 1238 FR_DTCCode "";
BA_ "EventCommandSignal" SG_ 1934 ADC_Diag_Response 1;
BA_ "GatewayedSignals" SG_ 1934 ADC_Diag_Response 0;
BA_ "GenSigInactiveValue" SG_ 1934 ADC_Diag_Response 0;
BA_ "GenSigInvalidValue" SG_ 1934 ADC_Diag_Response 0;
BA_ "GenSigSendType" SG_ 1934 ADC_Diag_Response 0;
BA_ "GenSigStartValue" SG_ 1934 ADC_Diag_Response 0;
BA_ "GenSigTimeoutValue" SG_ 1934 ADC_Diag_Response 0;
BA_ "Remark" SG_ 1934 ADC_Diag_Response "";
BA_ "EventCommandSignal" SG_ 1806 ADC_Diag_Request 0;
BA_ "GatewayedSignals" SG_ 1806 ADC_Diag_Request 0;
BA_ "GenSigInactiveValue" SG_ 1806 ADC_Diag_Request 0;
BA_ "GenSigInvalidValue" SG_ 1806 ADC_Diag_Request 0;
BA_ "GenSigSendType" SG_ 1806 ADC_Diag_Request 1;
BA_ "GenSigStartValue" SG_ 1806 ADC_Diag_Request 0;
BA_ "GenSigTimeoutValue" SG_ 1806 ADC_Diag_Request 0;
BA_ "Remark" SG_ 1806 ADC_Diag_Request "";
BA_ "EventCommandSignal" SG_ 1854 FR_Diag_Request 1;
BA_ "GatewayedSignals" SG_ 1854 FR_Diag_Request 0;
BA_ "GenSigInactiveValue" SG_ 1854 FR_Diag_Request 0;
BA_ "GenSigInvalidValue" SG_ 1854 FR_Diag_Request 0;
BA_ "GenSigSendType" SG_ 1854 FR_Diag_Request 0;
BA_ "GenSigStartValue" SG_ 1854 FR_Diag_Request 0;
BA_ "GenSigTimeoutValue" SG_ 1854 FR_Diag_Request 0;
BA_ "Remark" SG_ 1854 FR_Diag_Request "";
BA_ "EventCommandSignal" SG_ 2015 Fun_Diag_Request 0;
BA_ "GatewayedSignals" SG_ 2015 Fun_Diag_Request 0;
BA_ "GenSigInactiveValue" SG_ 2015 Fun_Diag_Request 0;
BA_ "GenSigInvalidValue" SG_ 2015 Fun_Diag_Request 0;
BA_ "GenSigSendType" SG_ 2015 Fun_Diag_Request 1;
BA_ "GenSigStartValue" SG_ 2015 Fun_Diag_Request 0;
BA_ "GenSigTimeoutValue" SG_ 2015 Fun_Diag_Request 0;
BA_ "Remark" SG_ 2015 Fun_Diag_Request "";
VAL_ 904 HVAC_RearDefrostSt 0 "Not acitve" 1 "Active"  ;
VAL_ 904 HVAC_WindExitMode 0 "Invalid" 1 "Face" 2 "Face/Foot" 3 "Foot" 4 "Foot/Defrost" 5 "Defrost" 6 "Face/DEF" 7 "Face/Foot/DEF"  ;
VAL_ 904 HVAC_CorrectedExterTempVD 0 "Not valid" 1 "Valid"  ;
VAL_ 904 HVAC_CorrectedCabinTempVD 0 "Not valid" 1 "Valid"  ;
VAL_ 904 WW_FwpFaultSt 0 "Not fault" 1 "Fault"  ;
VAL_ 904 WW_RwpFaultSt 0 "Not fault" 1 "Fault"  ;
VAL_ 904 WW_FwshFaultSt 0 "Not fault" 1 "Fault"  ;
VAL_ 904 WW_RwshFaultSt 0 "Not fault" 1 "Fault"  ;
VAL_ 904 WW_FwpAutoModeSt 0 "False" 1 "True"  ;
VAL_ 904 WW_RainFallLevel 0 "No Rain" 1 "Level 1" 2 "Level 2" 3 "Level 3" 4 "Level 4" 5 "Level 5" 6 "Level 6" 7 "Level 7" 8 "Level 8" 9 "Level 9" 10 "Level 10" 11 "Level 11" 12 "Level 12" 13 "Level 13" 14 "Init value" 15 "Invalid value"  ;
VAL_ 904 RLS_LightOnReq 0 "Light Off" 1 "Light On"  ;
VAL_ 904 RLS_LampOnReqValid 0 "Valid value" 1 "Invalid value"  ;
VAL_ 904 RLS_WiperSpd 0 "Switch Off" 1 "Low speed/speed 1" 2 "speed 2" 3 "speed 3" 4 "speed 4" 5 "speed 5" 6 "speed 6" 7 "speed 7" 8 "speed 8" 9 "speed 9" 10 "speed 10" 11 "speed 11" 12 "speed 12" 13 "speed 13" 14 "High speed/speed 14" 15 "Invalid"  ;
VAL_ 904 RLS_RainfallLevel 0 "No Rain" 1 "Level 1" 2 "Level 2" 3 "Level 3" 4 "Level 4" 5 "Level 5" 6 "Level 6" 7 "Level 7" 8 "Level 8" 9 "Level 9" 10 "Level 10" 11 "Level 11" 12 "Level 12" 13 "Level 13" 14 "Init value" 15 "Invalid value"  ;
VAL_ 904 RLS_RSErr 0 "No Error" 1 "Error"  ;
VAL_ 904 RLS_LSErr 0 "No Error" 1 "Error"  ;
VAL_ 904 PM_AUTHPstState 0 "Disable" 1 "Enable"  ;
VAL_ 904 CCU_FuncReq_SentryMod 0 "OFF" 1 "SentryModeWake"  ;
VAL_ 904 CCU_ModeSuppressSts 0 "OFF" 1 "ON" 2 "UNKNOWN"  ;
VAL_ 904 RLS_HUTErr 0 "HUT sensor normal" 1 "HUT sensor error"  ;
VAL_ 904 SR_SunroofCurrentPst 255 "Undefined Sunroof position"  ;
VAL_ 904 EL_LeftBSDIndicatorSt 0 "OFF" 1 "ON"  ;
VAL_ 904 UINM_HazardLightSwSt 0 "No Request" 1 "Request"  ;
VAL_ 904 EL_MLTurnLightSt 0 "Not active" 1 "OFF" 2 "ON" 3 "Not used"  ;
VAL_ 904 EL_MLTurnLightFaultSt 0 "Not fault" 1 "Fault"  ;
VAL_ 904 EL_LeftBSDIndicatorFaultSt 0 "Not fault" 1 "Fault"  ;
VAL_ 904 ZCUL_FrtWindshildHeatSt 0 "No" 1 "Heating" 2 "Fault" 3 "reserve"  ;
VAL_ 904 ACU_PCS_SVM_MODCmd 0 "Disable" 1 "Enalbe"  ;
VAL_ 904 ACU_HeadLightVirtualSwSt 0 "NotActive" 1 "PositionLight" 2 "LowBeam" 3 "AutoLight"  ;
VAL_ 904 ACU_FrontFogLightVirtualSwSt 0 "Not Active" 1 "Active"  ;
VAL_ 904 ACU_RearFogLightVirtualSwSt 0 "Not Active" 1 "Active"  ;
VAL_ 904 ACU_Account_Uid 0 "No command" 1 "account 0" 2 "account 1" 3 "account 2" 4 "account 3" 5 "account 4" 6 "account 5" 7 "account 6" 8 "account 7" 9 "account 8" 10 "Not used" 11 "Not used" 12 "Not used" 13 "Not used" 14 "Not used" 15 "Not used"  ;
VAL_ 904 ACU_IHBC_SwitchReq 0 "No command" 1 "Not active" 2 "Active" 3 "Not used"  ;
VAL_ 904 ACU_NDASwitchReq 0 "No command" 1 "Not active" 2 "Active" 3 "Not used"  ;
VAL_ 904 ACU_NDALCConSwitchReq 0 "No command" 1 "Need confirm" 2 "No need confirm" 3 "Not used"  ;
VAL_ 904 ACU_NDALCStySwitchReq 0 "No command" 1 "Standard" 2 "Radical" 3 "Not used"  ;
VAL_ 904 ACU_ADASWarnTypeSwitch 0 "No command" 1 "Sound" 2 "Voice" 3 "Seat vibration"  ;
VAL_ 904 ACU_iACC_StyleConfirmSwitchReq 0 "No Command" 1 "Need confirm" 2 "No need confirm" 3 "OFF"  ;
VAL_ 904 ACU_IFC_ISDRestOfdis 0 "not in ISD" 251 "over 70km"  ;
VAL_ 904 EL_MLADASLightSt 0 "Off" 1 "On" 2 "Fault" 3 "Not used"  ;
VAL_ 904 ACU_IFC_SpeedLimitUnit 0 "Not used" 1 "Km/h" 2 "Miles/h" 3 "Not used"  ;
VAL_ 904 ACU_ThemeType 0 "Day mode" 1 "Night mode"  ;
VAL_ 904 ACU_IFC_SpeedLimtType 0 "Not specific" 1 "Speed limit camera detection" 2 "Interval speed detectionlimit"  ;
VAL_ 904 ACU_IFC_RoadType 0 "unknown" 1 "High way" 2 "National road" 3 "Provincial road" 4 "County road" 5 "Village road" 6 "City express way" 7 "Major urban road" 8 "Secondary urban road" 9 "Normal urban road" 10 "Non-Navigation Road" 11 "Ramp" 12 "Reserve" 13 "Reserve" 14 "Reserve" 15 "Reserve"  ;
VAL_ 904 ACU_IFC_ZoneCode 0 "Not used" 1 "China"  ;
VAL_ 904 ACU_IFC_NaviSt 0 "Unknown" 1 "Cruise" 2 "Navigate" 3 "Failure"  ;
VAL_ 904 ACU_IFC_NaviCorp 0 "unknown" 1 "Gaode Map" 2 "Tescent Map" 3 "Baidu Map" 4 "Ruitu Map"  ;
VAL_ 904 ACU_IFC_NaviNewIconDis 0 "no newIcon ahead" 21 "over 2.0km"  ;
VAL_ 904 ACU_IFC_OfframpSt 0 "Not off-ramp" 1 "Off-ramp"  ;
VAL_ 904 ACU_IFC_NaviNewIcon 0 "unknown" 1 "left" 2 "right" 3 "left front" 4 "right front" 5 "left rear" 6 "right rear" 7 "left u-turn" 8 "right u-turn" 9 "go straight" 10 "roundabout entrance" 11 "roundabout exit" 12 "service area" 13 "toll station" 14 "tunnel" 15 "not used"  ;
VAL_ 904 ACU_IFC_SLCAheadDis 251 "over 1.25km"  ;
VAL_ 904 ACU_DVR_Switch 0 "Off" 1 "On"  ;
VAL_ 904 ACU_IFC_OfframpDis 254 "over 2km"  ;
VAL_ 904 DrvrSideMotResp 0 "No Action" 1 "Executing Retraction Assistance" 2 "Executing Clearance Removal 1" 3 "Executing Clearance Removal 2" 4 "Executing Dynamic Support 1" 5 "Executing Dynamic Support 2" 6 "Executing Pre-crash Protection" 7 "Executing Vibration Warning 1" 8 "Executing Vibration Warning 2" 9 "Reserved" 10 "Retraction Assistance Completed" 11 "Clearance Removal Completed" 12 "Executing Dynamic Support 3" 13 "Executing Dynamic Support 4" 14 "Reserved" 15 "Timeout"  ;
VAL_ 904 EL_LeftLowBeamSt 0 "OFF" 1 "ON"  ;
VAL_ 904 EL_LeftLowBeamFaultSt 0 "Not fault" 1 "Fault"  ;
VAL_ 904 EL_RightLowBeamSt 0 "OFF" 1 "ON"  ;
VAL_ 904 EL_RightLowBeamFaultSt 0 "Not fault" 1 "Fault"  ;
VAL_ 904 WW_FWPMotorSt 0 "Off" 1 "Reserve" 2 "Stall protection" 3 "Failure" 4 "Low speed" 5 "High speed" 6 "Hard stopped" 7 "Interval delaying"  ;
VAL_ 904 EL_FLTurnLightSt 0 "Not active" 1 "OFF" 2 "ON" 3 "Not used"  ;
VAL_ 904 EL_FLTurnLightFaultSt 0 "Not fault" 1 "Fault"  ;
VAL_ 904 EL_FRTurnLightSt 0 "Not active" 1 "OFF" 2 "ON" 3 "Not used"  ;
VAL_ 904 EL_FRTurnLightFaultSt 0 "Not fault" 1 "Fault"  ;
VAL_ 904 EL_SideBrkLightSt 0 "OFF" 1 "ON"  ;
VAL_ 904 EL_SideBrkLightFaultSt 0 "Not fault" 1 "Fault"  ;
VAL_ 904 EL_CHMSLSt 0 "OFF" 1 "ON"  ;
VAL_ 904 EL_CHMSLFaultSt 0 "Not fault" 1 "Fault"  ;
VAL_ 904 EL_RLTurnLightSt 0 "Not active" 1 "OFF" 2 "ON" 3 "Not used"  ;
VAL_ 904 EL_RLTurnLightFaultSt 0 "Not fault" 1 "Fault"  ;
VAL_ 904 EL_RRTurnLightSt 0 "Not active" 1 "OFF" 2 "ON" 3 "Not used"  ;
VAL_ 904 EL_RRTurnLightFaultSt 0 "Not fault" 1 "Fault"  ;
VAL_ 904 IPS_DCDCModeSt 7 "Failure;" 3 "Active - Buck Mode;" 2 "Connected (HV is active);" 1 "Disconnected;" 0 "Init;"  ;
VAL_ 904 IPDS_FRRadarPowerSup 0 "Not Active" 1 "Active" 2 "PreOFF" 3 "Invalid"  ;
VAL_ 904 IPDS_FLRadarPowerSup 0 "Not Active" 1 "Active" 2 "PreOFF" 3 "Invalid"  ;
VAL_ 904 IPDS_FrontRadarPowerSup 0 "Not Active" 1 "Active" 2 "PreOFF" 3 "Invalid"  ;
VAL_ 904 IPDS_HDMapPowerSup 0 "Not Active" 1 "Active" 2 "PreOFF" 3 "Invalid"  ;
VAL_ 904 IPDS_RearRadarPowerSup 0 "Not Active" 1 "Active" 2 "PreOFF" 3 "Invalid"  ;
VAL_ 1359 CCU_NMCBV 0 "Node has not woken up the    network(passive wakeup);" 1 "Node has woken up the network(active wakeup)" 0 "NM PDU contains no Partial Network request information" 1 "NM PDU contains Partial Network request information"  ;
VAL_ 1359 CCU_NMWakeupOrigin 0 "Reserved" 1 "CAN channel 0" 2 "CAN channel 1" 3 "CAN channel 2" 4 "CAN channel 3" 5 "CAN channel 4" 6 "CAN channel 5" 7 "CAN channel 6" 8 "CAN channel 7" 9 "CAN channel 8" 10 "CAN channel 9" 11 "CAN channel 10" 12 "CAN channel 11" 13 "CAN channel 12" 14 "CAN channel 13" 15 "CAN channel 14" 16 "CAN channel 15" 17 "Reserved" 18 "Reserved" 19 "Reserved" 20 "AcoreRequest" 21 "Reserved" 22 "Reserved" 23 "Reserved" 24 "Reserved" 25 "Reserved" 26 "Reserved" 27 "Reserved" 28 "Reserved" 29 "Reserved" 30 "Reserved" 31 "Reserved" 32 "Reserved" 33 "Reserved" 34 "Reserved" 35 "Reserved" 36 "Reserved" 37 "Reserved" 38 "Reserved" 39 "Reserved" 40 "Reserved" 41 "Reserved" 42 "Reserved" 43 "Reserved" 44 "Reserved" 45 "Reserved" 46 "Reserved" 47 "Reserved" 48 "Reserved" 49 "Reserved" 50 "UsageModeSt" 51 "NMiDPSNMKeepAwakeFlag" 52 "NMEEMKeepAwakeFlag" 53 "NMEEMKeepAwakeFlag_Aux" 54 "NMVCUGlobalKeepAwakeFlag" 55 "NMVCUChargingKeepAwakeFlag（新能源，VCU_hcu）" 56 "DoIPActiveLineStatus" 57 "NMBMSGlobalKeepAwakeFlag" 58 "NMBMSChargingKeepAwakeFlag" 59 "NMBMSThermalRunawayKeepAwakeFlag（新能源，BMS）" 60 "Reserved" 61 "NMBMSThermalRunawayKeepAwakeFlag （动力，VCU_slccu）" 62 "NMVCUChargingKeepAwakeFlag（动力，VCU_slccu）" 63 "NMVCU2GlobalKeepAwakeFlag" 64 "NMVHMKeepAwakeFlag" 65 "Reserved" 66 "CSM_RC_KeepAwake" 67 "NMHVACKeepAwakeFlag（新能源，TMS）" 68 "Reserved" 69 "Reserved" 70 "BDC_NMBDCKeepAwakeFlag" 71 "NMTMSChargingKeepAwakeFlag" 72 "NMTMSGlobalKeepAwakeFlag" 73 "Reserved" 74 "Reserved" 75 "Reserved" 76 "Reserved" 77 "Reserved" 78 "Reserved" 79 "Reserved" 80 "Reserved" 81 "Reserved" 82 "Reserved" 83 "Reserved" 84 "Reserved" 85 "Reserved" 86 "Reserved" 87 "Reserved" 88 "Reserved" 89 "NMWCCDownloadRequest_RT1" 90 "CAN7_DiagMSG_ID ！" 91 "CAN7_DiagMSG_ID" 92 "Reserved" 93 "Reserved" 94 "Reserved" 95 "Reserved" 96 "Reserved" 97 "Reserved" 98 "Reserved" 99 "Reserved" 100 "NMATWSKeepAwakeFlag" 101 "NMExteriorLightKeepAwakeFlag" 102 "NMLockingKeepAwakeFlag" 103 "NMPWLKeepAwakeFlag" 104 "NMSunRoofKeepAwakeFlag" 105 "NMPLGKeepAwakeFlag" 106 "NMPowerOperatedDoorKeepAwakeFlag" 107 "MR_NMMirrorKeepAwakeFlag" 108 "NMSeatControlKeepAwakeFlag" 109 "NMHVACKeepAwakeFlag" 110 "NMHVACRLSLinAwakeFlag" 111 "NMAQCKeepAwakeFlag" 112 "NMTPMSKeepAwakeFlag" 113 "ILC_NMKeepAwakeFlag" 114 "NMESMKeepAwakeFlag" 115 "NMKAEKeepAwakeFlag" 116 "NMVRMPNCCharingKeepAwakeFlag" 140 "NMWCCDownloadReques_RT2"  ;
VAL_ 1359 CCU_PNCInformation0 0 "No request" 1 "Request" 0 "No request" 1 "Request" 0 "No request" 1 "Request" 0 "No request" 1 "Request" 0 "No request" 1 "Request" 0 "No request" 1 "Request" 0 "No request" 1 "Request"  ;
VAL_ 1359 CCU_PNCInformation1 0 "No request" 1 "Request" 0 "No request" 1 "Request"  ;
VAL_ 1294 ADC_NMCBV 0 "Node has not woken up the    network(passive wakeup);" 1 "Node has woken up the network(active wakeup)" 0 "NM PDU contains no Partial Network request information" 1 "NM PDU contains Partial Network request information"  ;
VAL_ 1294 ADC_NMWakeupOrigin 1 "NM Message wakeup" 2 "Diagnostic Message" 3 "KL15"  ;
VAL_ 1294 ADC_PNCInformation0 0 "No request" 1 "Request" 0 "No request" 1 "Request" 0 "No request" 1 "Request" 0 "No request" 1 "Request" 0 "No request" 1 "Request" 0 "No request" 1 "Request" 0 "No request" 1 "Request"  ;
VAL_ 1294 ADC_PNCInformation1 0 "No request" 1 "Request" 0 "No request" 1 "Request"  ;
VAL_ 1354 RLR_NMCBV 0 "Node has not woken up the    network(passive wakeup);" 1 "Node has woken up the network(active wakeup)" 0 "NM PDU contains no Partial Network request information" 1 "NM PDU contains Partial Network request information"  ;
VAL_ 1354 RLR_PNCInformation0 0 "No request" 1 "Request" 0 "No request" 1 "Request" 0 "No request" 1 "Request" 0 "No request" 1 "Request" 0 "No request" 1 "Request" 0 "No request" 1 "Request" 0 "No request" 1 "Request"  ;
VAL_ 1354 RLR_PNCInformation1 0 "No request" 1 "Request" 0 "No request" 1 "Request"  ;
VAL_ 1343 RRR_NMCBV 0 "Node has not woken up the    network(passive wakeup);" 1 "Node has woken up the network(active wakeup)" 0 "NM PDU contains no Partial Network request information" 1 "NM PDU contains Partial Network request information"  ;
VAL_ 1343 RRR_PNCInformation0 0 "No request" 1 "Request" 0 "No request" 1 "Request" 0 "No request" 1 "Request" 0 "No request" 1 "Request" 0 "No request" 1 "Request" 0 "No request" 1 "Request" 0 "No request" 1 "Request"  ;
VAL_ 1343 RRR_PNCInformation1 0 "No request" 1 "Request" 0 "No request" 1 "Request"  ;
